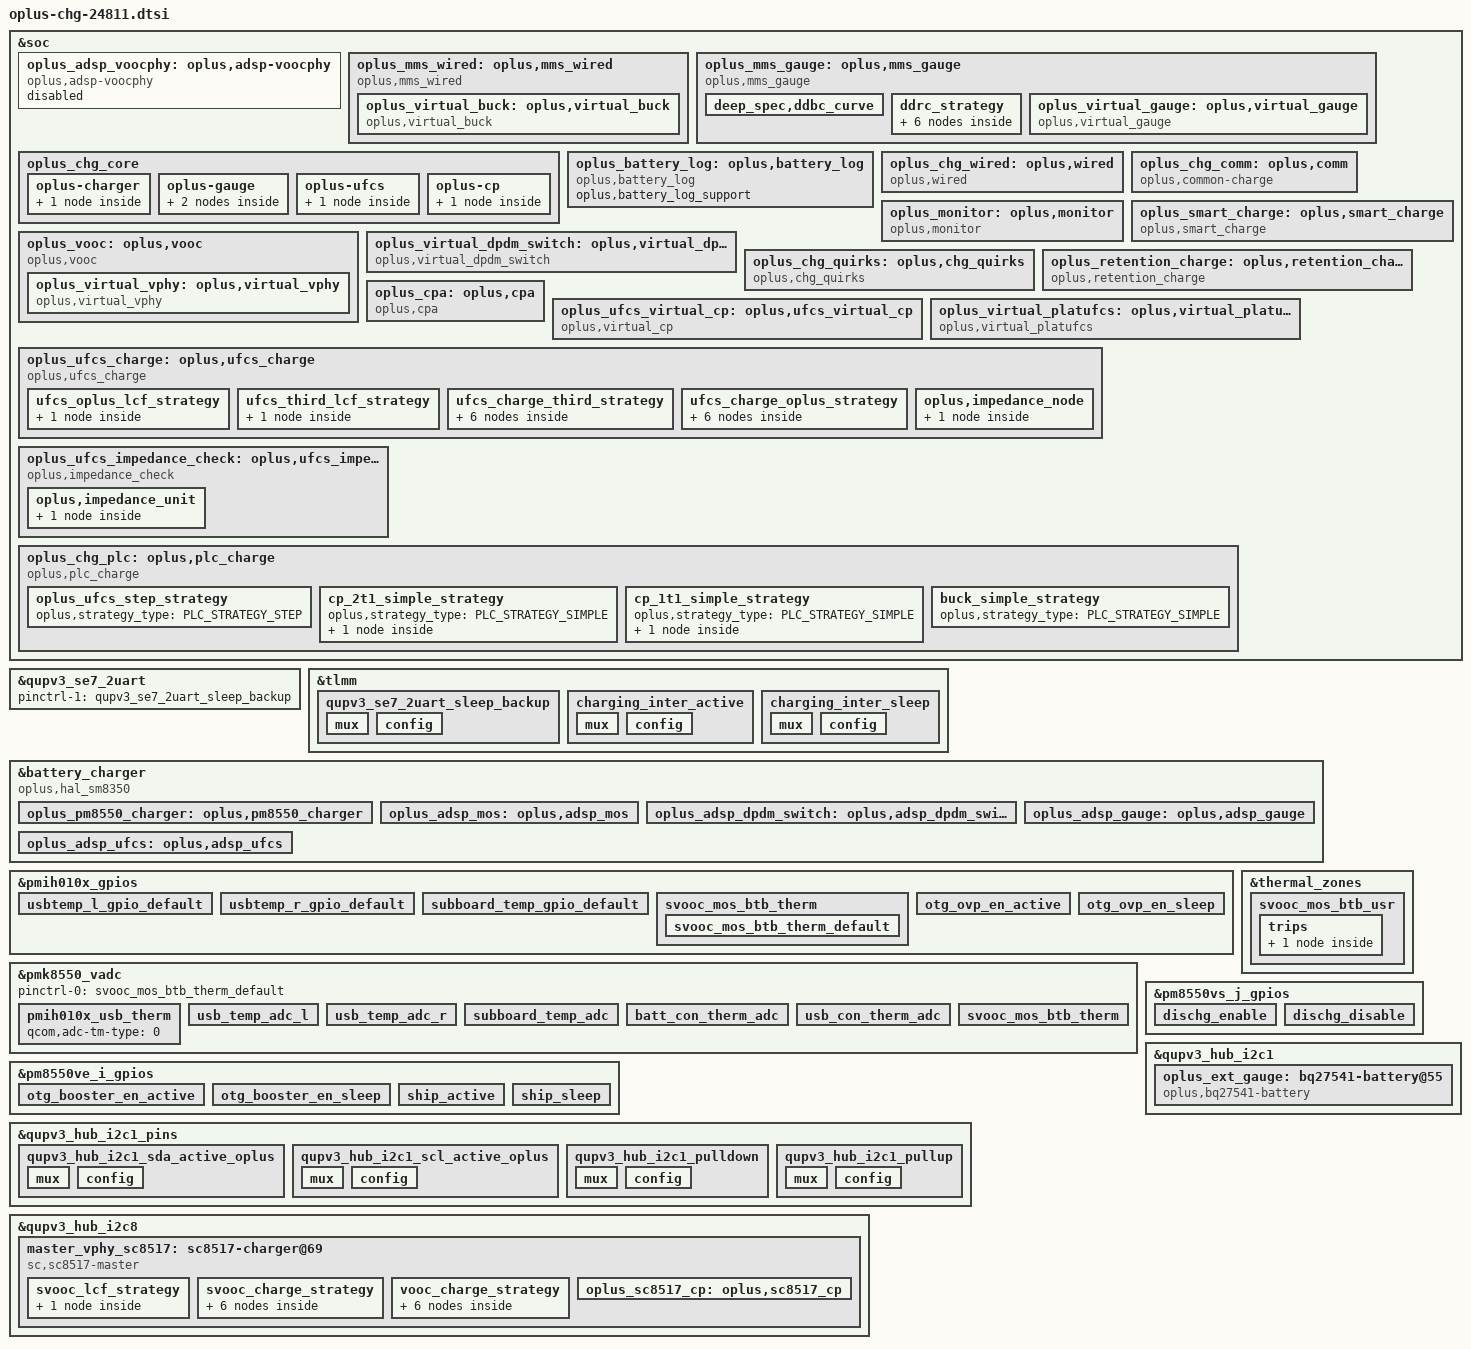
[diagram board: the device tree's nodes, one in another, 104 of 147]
//ifdef OPLUS_FEATURE_CHG_BASIC
//BSP.CHG.Basic, 2023/04/19, sjc Add for charging

#include "oplus-chg-8750.h.dtsi"
#include "oplus-chg-24019-fw.dtsi"

/*
 * NOTICE:
 * sector 1: wired charging
 * sector 2: ufcs
 * sector 3: pps
 */

//#ifdef OPLUS_FEATURE_CHG_BASIC /* BSP.CHG.Basic, 2023/04/19, sjc Add for wired charging */
//for wired charging config
&soc {
	oplus_adsp_voocphy: oplus,adsp-voocphy {
		status = "disabled";
		compatible = "oplus,adsp-voocphy";
	};

	oplus_mms_wired: oplus,mms_wired {
		compatible = "oplus,mms_wired";
		oplus,buck_ic = <&oplus_virtual_buck>;
		oplus,voocphy_ic = <&oplus_virtual_vphy>;

		oplus,adc_info_name = "855";
		oplus,topic-update-interval = <5000>;
		high-temp-scheme;

		oplus,support_usbtemp_protect_v2;
		oplus_spec,usbtemp_batt_temp_low = <50>;
		oplus_spec,usbtemp_batt_temp_high = <50>;
		oplus_spec,usbtemp_batt_temp_over_hot = <60>;
		oplus_spec,usbtemp_ntc_temp_low = <57>;
		oplus_spec,usbtemp_ntc_temp_high = <69>;
		oplus_spec,usbtemp_temp_gap_low_with_batt_temp = <7>;
		oplus_spec,usbtemp_temp_gap_with_batt_temp_in_over_hot = <15>;
		oplus_spec,usbtemp_temp_gap_high_with_batt_temp = <12>;
		oplus_spec,usbtemp_temp_gap_low_without_batt_temp = <12>;
		oplus_spec,usbtemp_temp_gap_high_without_batt_temp = <24>;
		oplus_spec.usbtemp_rise_fast_temp_low = <3>;
		oplus_spec.usbtemp_rise_fast_temp_high = <3>;
		oplus_spec.usbtemp_rise_fast_temp_count_low = <30>;
		oplus_spec.usbtemp_rise_fast_temp_count_high = <20>;
		oplus_spec,usbtemp_cool_down_ntc_low = <54>;
		oplus_spec,usbtemp_cool_down_ntc_high = <65>;
		oplus_spec,usbtemp_cool_down_gap_low = <12>;
		oplus_spec,usbtemp_cool_down_gap_high = <20>;
		oplus_spec,usbtemp_cool_down_recover_ntc_low = <48>;
		oplus_spec,usbtemp_cool_down_recover_ntc_high = <60>;
		oplus_spec,usbtemp_cool_down_recover_gap_low = <6>;
		oplus_spec,usbtemp_cool_down_recover_gap_high = <15>;
		oplus_spec,usbtemp_otg_cc_boot_current_limit = <1250>;

		oplus_virtual_buck: oplus,virtual_buck {
			compatible = "oplus,virtual_buck";
			oplus,buck_ic = <&oplus_pm8550_charger>;
			oplus,buck_ic_index = <0>;
			oplus,buck_ic_connect = <OPLUS_CHG_IC_CONNECT_PARALLEL>;
			oplus,main_charger = <1>;
			oplus,buck_ic_current_ratio = <100>;
			oplus,buck_ic_func_group = <&plat_pm8550_groups>;

			oplus,ic_type = <OPLUS_CHG_IC_VIRTUAL_BUCK>;
			oplus,ic_index = <0>;

			oplus,dischg-gpio = <&pm8550vs_j_gpios 6 0x00>;
			oplus,ship-gpio = <&pm8550ve_i_gpios 7 0x00>;
			oplus,usbtemp_conversion_ratio = <10>;

			pinctrl-names = "usbtemp_l_gpio_default", "usbtemp_r_gpio_default",
						"dischg_enable", "dischg_disable",
						"ship_active", "ship_sleep";
			pinctrl-0 = <&usbtemp_l_gpio_default>;
			pinctrl-1 = <&usbtemp_r_gpio_default>;
			pinctrl-2 = <&dischg_enable>;
			pinctrl-3 = <&dischg_disable>;
			pinctrl-4 = <&ship_active>;
			pinctrl-5 = <&ship_sleep>;

			io-channels = <&pmk8550_vadc PMIH010X_ADC5_GEN4_AMUX1_GPIO6_100K_PU>,
					      <&pmk8550_vadc PMIH010X_ADC5_GEN4_AMUX5_GPIO18_100K_PU>;
			io-channel-names = "usb_temp_adc_l", "usb_temp_adc_r";

			oplus,uart_tx-gpio = <&tlmm 62 0x00>;
			oplus,uart_rx-gpio = <&tlmm 63 0x00>;
		};
	};
	oplus_mms_gauge: oplus,mms_gauge {
		compatible = "oplus,mms_gauge";
		oplus,gauge_ic = <&oplus_virtual_gauge>;
		oplus,topic-update-interval = <5000>;
		oplus,support_subboard_ntc;

		deep_spec,support;
		deep_spec,uv_thr = <3000>;
		deep_spec,count_thr = <50>;
		deep_spec,vbat_soc = <20>;
		deep_spec,count_step = <0 10 0
					350 12 1
					450 15 2
					530 20 3>;

		deep_spec,term_coeff = <3000 800 4
					3100 900 6
					3200 1000 9
					3300 1100 10>;
		deep_spec,ddrc_strategy_name = "ddrc_curve";
		deep_spec,volt_step = <20>;
		deep_spec,ddbc_curve {
			oplus,temp_type = <OPLUS_STRATEGY_USE_BATT_TEMP>;
			oplus,temp_range = <(-100) 50 200>;
			deep_spec,ddbc_temp_cold = <500 3250 5
						   10000 3200 2>;
			deep_spec,ddbc_temp_cool = <500 3250 5
						   10000 3200 2>;
			deep_spec,ddbc_temp_normal = <500 3350 5
						   10000 3300 2>;
			deep_spec,ddbc_temp_warm = <500 3350 5
						   10000 3300 2>;
		};
		ddrc_strategy {
			oplus,temp_type = <OPLUS_STRATEGY_USE_BATT_TEMP>;
			oplus,ratio_range = <20 30 50 70 90>;
			oplus,temp_range = <(-50) 100 350>;
			strategy_ratio_range_min {
				strategy_temp_cold =	<0 3000 3000 0
							15 3000 3000 1
							1200 3100 3100 2
							1600 3200 3200 3
							2000 3300 3300 4>;
				strategy_temp_cool =	<0 3000 3000 0
							15 3000 3000 1
							500 3000 3000 2
							1000 3100 3100 3
							1500 3200 3200 4
							2000 3300 3300 5>;
				strategy_temp_normal =	<0 3000 3000 0
							15 3000 3000 1
							500 3100 3100 2
							1000 3200 3200 3
							1500 3300 3300 4>;
				strategy_temp_warm =	<0 3000 3000 0
							15 3000 3000 1
							500 3100 3100 2
							1000 3200 3200 3
							1500 3300 3300 4>;
			};
			strategy_ratio_range_low {
				strategy_temp_cold =	<0 3000 3000 0
							15 3000 3000 1
							1000 3100 3100 2
							1300 3200 3200 3
							1600 3300 3300 4>;
				strategy_temp_cool =	<0 3000 3000 0
							15 3000 3000 1
							400 3000 3000 2
							800 3100 3100 3
							1200 3200 3200 4
							1600 3300 3300 5>;
				strategy_temp_normal =	<0 3000 3000 0
							15 3000 3000 1
							400 3100 3100 2
							800 3200 3200 3
							1200 3300 3300 4>;
				strategy_temp_warm =	<0 3000 3000 0
							15 3000 3000 1
							400 3100 3100 2
							800 3200 3200 3
							1200 3300 3300 4>;
			};
			strategy_ratio_range_mid_low {
				strategy_temp_cold =	<0 3000 3000 0
							15 3000 3000 1
							600 3100 3100 2
							900 3200 3200 3
							1200 3300 3300 4>;
				strategy_temp_cool =	<0 3000 3000 0
							15 3000 3000 1
							300 3100 3100 2
							600 3200 3200 3
							900 3200 3200 4
							1200 3300 3300 5>;
				strategy_temp_normal =	<0 3000 3000 0
							15 3000 3000 1
							300 3100 3100 2
							600 3200 3200 3
							900 3300 3300 4>;
				strategy_temp_warm =	<0 3000 3000 0
							15 3000 3000 1
							300 3100 3100 2
							600 3200 3200 3
							900 3300 3300 4>;
			};
			strategy_ratio_range_mid {
				strategy_temp_cold =	<0 3000 3000 0
							15 3000 3000 1
							400 3100 3100 2
							700 3200 3200 3
							1000 3300 3300 4>;
				strategy_temp_cool =	<0 3000 3000 0
							100 3000 3000 1
							200 3100 3100 2
							500 3200 3200 3
							800 3300 3300 4>;
				strategy_temp_normal =	<0 3000 3000 0
							100 3100 3100 1
							200 3200 3200 2
							500 3300 3300 3>;
				strategy_temp_warm =	<0 3000 3000 0
							100 3100 3100 1
							200 3200 3200 2
							500 3300 3300 3>;
			};
			strategy_ratio_range_mid_high {
				strategy_temp_cold =	<0 3000 3000 0
							15 3000 3000 1
							150 3100 3100 2
							300 3200 3200 3
							500 3300 3300 4>;
				strategy_temp_cool =	<0 3000 3000 0
							50 3000 3000 1
							100 3100 3100 2
							150 3200 3200 3
							300 3300 3300 4>;
				strategy_temp_normal =	<0 3000 3000 0
							50 3100 3100 1
							100 3200 3200 2
							150 3300 3300 3>;
				strategy_temp_warm =	<0 3000 3000 0
							50 3100 3100 1
							100 3200 3200 2
							150 3300 3300 3>;
			};
			strategy_ratio_range_high {
				strategy_temp_cold =	<0 3000 3000 0
							15 3000 3000 1
							150 3100 3100 2
							300 3200 3200 3
							500 3300 3300 4>;
				strategy_temp_cool =	<0 3000 3000 0
							50 3000 3000 1
							100 3100 3100 2
							150 3200 3200 3
							300 3300 3300 4>;
				strategy_temp_normal =	<0 3000 3000 0
							50 3100 3100 1
							100 3200 3200 2
							150 3300 3300 3>;
				strategy_temp_warm =	<0 3000 3000 0
							50 3100 3100 1
							100 3200 3200 2
							150 3300 3300 3>;
			};
		};

		oplus_virtual_gauge: oplus,virtual_gauge {
			compatible = "oplus,virtual_gauge";
			oplus,gauge_ic = <&oplus_ext_gauge  &oplus_adsp_gauge>;
			oplus,gauge_ic_index = <0 1>;
			oplus,gauge_ic_func_group = <&bq27541_groups &oplus_adsp_gauge_groups>;
			oplus,batt_capacity_mah = <6100>;
			oplus,ic_type = <OPLUS_CHG_IC_VIRTUAL_GAUGE>;
			oplus,ic_index = <0>;
		};
	};
};

&soc {
	oplus_chg_core {
		oplus,chg_framework_v2;
		oplus,battery_type_by_smem;
		oplus,smart_charging_screenoff;
		oplus,chg_spec_version = <OPLUS_CHG_SPEC_VER_V3P7>;
		oplus,common-charge-icl-support;

		oplus-charger {
			plat_pm8550_groups: oplus,plat_pm8550-groups {
				functions = <
					OPLUS_IC_FUNC_INIT
					OPLUS_IC_FUNC_EXIT
					OPLUS_IC_FUNC_REG_DUMP
					OPLUS_IC_FUNC_SMT_TEST
					OPLUS_IC_FUNC_BUCK_INPUT_PRESENT
					OPLUS_IC_FUNC_BUCK_INPUT_SUSPEND
					OPLUS_IC_FUNC_BUCK_INPUT_IS_SUSPEND
					OPLUS_IC_FUNC_BUCK_OUTPUT_SUSPEND
					OPLUS_IC_FUNC_BUCK_OUTPUT_IS_SUSPEND
					OPLUS_IC_FUNC_BUCK_GET_CC_ORIENTATION
					OPLUS_IC_FUNC_BUCK_GET_CHARGER_TYPE
					OPLUS_IC_FUNC_BUCK_RERUN_BC12
					OPLUS_IC_FUNC_BUCK_QC_DETECT_ENABLE
					OPLUS_IC_FUNC_BUCK_SHIPMODE_ENABLE
					OPLUS_IC_FUNC_BUCK_SET_QC_CONFIG
					OPLUS_IC_FUNC_BUCK_SET_PD_CONFIG
					OPLUS_IC_FUNC_GET_SHUTDOWN_SOC
					OPLUS_IC_FUNC_BACKUP_SOC
					OPLUS_IC_FUNC_GET_TYPEC_MODE
					OPLUS_IC_FUNC_BUCK_SET_ICL
					OPLUS_IC_FUNC_BUCK_GET_ICL
					OPLUS_IC_FUNC_BUCK_SET_FCC
					OPLUS_IC_FUNC_BUCK_SET_FV
					OPLUS_IC_FUNC_BUCK_SET_ITERM
					OPLUS_IC_FUNC_BUCK_SET_RECHG_VOL
					OPLUS_IC_FUNC_BUCK_GET_INPUT_CURR
					OPLUS_IC_FUNC_BUCK_GET_INPUT_VOL
					OPLUS_IC_FUNC_GET_CHARGER_CYCLE
					OPLUS_IC_FUNC_OTG_BOOST_ENABLE
					OPLUS_IC_FUNC_SET_OTG_BOOST_CURR_LIMIT
					OPLUS_IC_FUNC_BUCK_GET_VBUS_COLLAPSE_STATUS
					OPLUS_IC_FUNC_GET_OTG_ENABLE
					OPLUS_IC_FUNC_SET_OTG_SWITCH_STATUS
					OPLUS_IC_FUNC_GET_OTG_SWITCH_STATUS
					OPLUS_IC_FUNC_GET_OTG_ONLINE_STATUS
					OPLUS_IC_FUNC_BUCK_GET_HW_DETECT
					OPLUS_IC_FUNC_VOOCPHY_SET_MATCH_TEMP
					OPLUS_IC_FUNC_IS_OPLUS_SVID
					OPLUS_IC_FUNC_BUCK_SET_VINDPM
					OPLUS_IC_FUNC_WLS_BOOST_ENABLE
					OPLUS_IC_FUNC_SET_WLS_BOOST_VOL
					OPLUS_IC_FUNC_SET_WLS_BOOST_CURR_LIMIT
					OPLUS_IC_FUNC_BUCK_WLS_INPUT_SUSPEND
					OPLUS_IC_FUNC_BUCK_SET_WLS_ICL
					OPLUS_IC_FUNC_BUCK_GET_WLS_ICL
					OPLUS_IC_FUNC_BUCK_GET_WLS_INPUT_CURR
					OPLUS_IC_FUNC_BUCK_GET_WLS_INPUT_VOL
					OPLUS_IC_FUNC_BUCK_WLS_AICL_ENABLE
					OPLUS_IC_FUNC_BUCK_WLS_AICL_RERUN
					OPLUS_IC_FUNC_BUCK_DIS_INSERT_DETECT
					OPLUS_IC_FUNC_GET_TYPEC_ROLE
					OPLUS_IC_FUNC_SET_TYPEC_MODE
					OPLUS_IC_FUNC_BUCK_GET_USB_BTB_TEMP
					OPLUS_IC_FUNC_BUCK_GET_BATT_BTB_TEMP
					OPLUS_IC_FUNC_BUCK_GET_USB_AICL_ENHANCE
					OPLUS_IC_FUNC_BUCK_SET_AICL_POINT
				>;
				virqs = <
					OPLUS_IC_VIRQ_ERR
					OPLUS_IC_VIRQ_CC_DETECT
					OPLUS_IC_VIRQ_PLUGIN
					OPLUS_IC_VIRQ_CC_CHANGED
					OPLUS_IC_VIRQ_SUSPEND_CHECK
					OPLUS_IC_VIRQ_CHG_TYPE_CHANGE
					OPLUS_IC_VIRQ_OTG_ENABLE
					OPLUS_IC_VIRQ_SVID
				>;
			};
		};

		oplus-gauge {
			bq27541_groups: oplus,bq27541_groups {
				functions = <
					OPLUS_IC_FUNC_INIT
					OPLUS_IC_FUNC_EXIT
					OPLUS_IC_FUNC_REG_DUMP
					OPLUS_IC_FUNC_SMT_TEST
					OPLUS_IC_FUNC_GAUGE_GET_BATT_VOL
					OPLUS_IC_FUNC_GAUGE_GET_BATT_MAX
					OPLUS_IC_FUNC_GAUGE_GET_BATT_MIN
					OPLUS_IC_FUNC_GAUGE_GET_BATT_CURR
					OPLUS_IC_FUNC_GAUGE_GET_BATT_TEMP
					OPLUS_IC_FUNC_GAUGE_GET_BATT_SOC
					OPLUS_IC_FUNC_GAUGE_GET_BATT_FCC
					OPLUS_IC_FUNC_GAUGE_GET_BATT_CC
					OPLUS_IC_FUNC_GAUGE_GET_BATT_RM
					OPLUS_IC_FUNC_GAUGE_GET_BATT_SOH
					OPLUS_IC_FUNC_GAUGE_GET_BATT_AUTH
					OPLUS_IC_FUNC_GAUGE_GET_BATT_HMAC
					OPLUS_IC_FUNC_GAUGE_SET_BATT_FULL
					OPLUS_IC_FUNC_GAUGE_UPDATE_DOD0
					OPLUS_IC_FUNC_GAUGE_UPDATE_SOC_SMOOTH
					OPLUS_IC_FUNC_GAUGE_GET_CB_STATUS
					OPLUS_IC_FUNC_GAUGE_GET_BATT_NUM
					OPLUS_IC_FUNC_GAUGE_GET_DEVICE_TYPE
					OPLUS_IC_FUNC_GAUGE_GET_DEVICE_TYPE_FOR_VOOC
					OPLUS_IC_FUNC_GAUGE_GET_BATT_FCC
					OPLUS_IC_FUNC_GAUGE_GET_BATT_FC
					OPLUS_IC_FUNC_GAUGE_GET_BATT_QM
					OPLUS_IC_FUNC_GAUGE_GET_BATT_PD
					OPLUS_IC_FUNC_GAUGE_GET_BATT_RCU
					OPLUS_IC_FUNC_GAUGE_GET_BATT_RCF
					OPLUS_IC_FUNC_GAUGE_GET_BATT_FCU
					OPLUS_IC_FUNC_GAUGE_GET_BATT_FCF
					OPLUS_IC_FUNC_GAUGE_GET_BATT_SOU
					OPLUS_IC_FUNC_GAUGE_GET_BATT_DO0
					OPLUS_IC_FUNC_GAUGE_GET_BATT_DOE
					OPLUS_IC_FUNC_GAUGE_GET_BATT_TRM
					OPLUS_IC_FUNC_GAUGE_GET_BATT_PC
					OPLUS_IC_FUNC_GAUGE_GET_BATT_QS
					OPLUS_IC_FUNC_GAUGE_IS_SUSPEND
					OPLUS_IC_FUNC_GAUGE_GET_BCC_PARMS
					OPLUS_IC_FUNC_GAUGE_FASTCHG_UPDATE_BCC_PARMS
					OPLUS_IC_FUNC_GAUGE_GET_PREV_BCC_PARMS
					OPLUS_IC_FUNC_GAUGE_SET_BCC_PARMS
					OPLUS_IC_FUNC_GAUGE_SET_PROTECT_CHECK
					OPLUS_IC_FUNC_GAUGE_GET_AFI_UPDATE_DONE
					OPLUS_IC_FUNC_GAUGE_CHECK_RESET
					OPLUS_IC_FUNC_GAUGE_SET_RESET
					OPLUS_IC_FUNC_GAUGE_GET_DEVICE_TYPE_FOR_BCC
					OPLUS_IC_FUNC_GAUGE_GET_DOD0
					OPLUS_IC_FUNC_GAUGE_GET_DOD0_PASSED_Q
					OPLUS_IC_FUNC_GAUGE_GET_QMAX
					OPLUS_IC_FUNC_GAUGE_GET_QMAX_PASSED_Q
					OPLUS_IC_FUNC_GAUGE_GET_REG_INFO
					OPLUS_IC_FUNC_GAUGE_GET_CALIB_TIME
					OPLUS_IC_FUNC_GAUGE_GET_DEEP_DISCHG_COUNT
					OPLUS_IC_FUNC_GAUGE_SET_DEEP_DISCHG_COUNT
					OPLUS_IC_FUNC_GAUGE_GET_DEEP_TERM_VOLT
					OPLUS_IC_FUNC_GAUGE_SET_DEEP_TERM_VOLT
					OPLUS_IC_FUNC_GAUGE_SET_SILI_SPARE_POWER
					OPLUS_IC_FUNC_GAUGE_GET_SILI_SIMULATE_TERM_VOLT
					OPLUS_IC_FUNC_GAUGE_GET_SILI_IC_ALG_TERM_VOLT
					OPLUS_IC_FUNC_GAUGE_SET_SILI_IC_ALG_CFG
					OPLUS_IC_FUNC_GAUGE_GET_SILI_IC_ALG_DSG_ENABLE
					OPLUS_IC_FUNC_GAUGE_SET_SILI_IC_ALG_TERM_VOLT
					OPLUS_IC_FUNC_GAUGE_GET_SILI_ALG_APPLICATION_INFO
					OPLUS_IC_FUNC_GAUGE_GET_SILI_LIFETIME_STATUS
					OPLUS_IC_FUNC_GAUGE_GET_SILI_LIFETIME_INFO
					OPLUS_IC_FUNC_GAUGE_SET_LAST_CC
					OPLUS_IC_FUNC_GAUGE_GET_LAST_CC
					OPLUS_IC_FUNC_GAUGE_GET_CHEM_ID
				>;
				virqs = <
					OPLUS_IC_VIRQ_ERR
					OPLUS_IC_VIRQ_OFFLINE
					OPLUS_IC_VIRQ_RESUME
				>;
			};
			oplus_adsp_gauge_groups: oplus,oplus_adsp_gauge_groups {
				functions = <
					OPLUS_IC_FUNC_INIT
					OPLUS_IC_FUNC_EXIT
					OPLUS_IC_FUNC_REG_DUMP
					OPLUS_IC_FUNC_SMT_TEST
					OPLUS_IC_FUNC_GAUGE_GET_SUBBOARD_TEMP
				>;
				virqs = <
					OPLUS_IC_VIRQ_ERR
				>;
			};
		};

		oplus-ufcs {
			adsp_ufcs_groups: oplus,ufcs_groups {
				functions = <
					OPLUS_IC_FUNC_INIT
					OPLUS_IC_FUNC_EXIT
					OPLUS_IC_FUNC_REG_DUMP
					OPLUS_IC_FUNC_SMT_TEST
					OPLUS_IC_FUNC_UFCS_HANDSHAKE
					OPLUS_IC_FUNC_UFCS_PDO_SET
					OPLUS_IC_FUNC_UFCS_HARD_RESET
					OPLUS_IC_FUNC_UFCS_EXIT
					OPLUS_IC_FUNC_UFCS_CONFIG_WD
					OPLUS_IC_FUNC_UFCS_GET_DEV_INFO
					OPLUS_IC_FUNC_UFCS_GET_ERR_INFO
					OPLUS_IC_FUNC_UFCS_GET_SRC_INFO
					OPLUS_IC_FUNC_UFCS_GET_CABLE_INFO
					OPLUS_IC_FUNC_UFCS_GET_PDO_INFO
					OPLUS_IC_FUNC_UFCS_VERIFY_ADAPTER
					OPLUS_IC_FUNC_UFCS_GET_POWER_CHANGE_INFO
					OPLUS_IC_FUNC_UFCS_GET_EMARK_INFO
					OPLUS_IC_FUNC_UFCS_GET_POWER_INFO_EXT
					OPLUS_IC_FUNC_UFCS_IS_TEST_MODE
				>;
				virqs = <
					OPLUS_IC_VIRQ_ERR
					OPLUS_IC_VIRQ_ONLINE
					OPLUS_IC_VIRQ_OFFLINE
				>;
			};
		};

		oplus-cp {
			adsp_mos_groups: oplus,mos_groups {
			functions = <
					OPLUS_IC_FUNC_INIT
					OPLUS_IC_FUNC_EXIT
					OPLUS_IC_FUNC_CP_GET_TEMP
				>;
				virqs = <
					OPLUS_IC_VIRQ_ERR
					OPLUS_IC_VIRQ_ONLINE
					OPLUS_IC_VIRQ_OFFLINE
				>;
			};
		};
	};
};

&qupv3_se7_2uart {
	pinctrl-1 = <&qupv3_se7_2uart_sleep_backup>;
	status = "okay";
};

&tlmm {
	qupv3_se7_2uart_sleep_backup:qupv3_se7_2uart_sleep_backup {
		mux {
			pins = "gpio62", "gpio63";
			function = "gpio";
		};

		config {
			pins = "gpio62", "gpio63";
			drive-strength = <2>;
			bias-disable;
			input-enable;
		};
	};
};

&battery_charger {
	//for oplus chg framework:
	oplus,chg_ops = "plat-pmic";
	qcom,pmic_ftm_vph = "/sys/bus/spmi/drivers/pmic-spmi/0-00/c42d000.qcom,spmi:qcom,pmk8550@0:vadc@9000/iio:device0/in_voltage_pmih010x_vph_pwr_input";
	qcom,pmic_ftm_vbat = "/sys/bus/spmi/drivers/pmic-spmi/0-00/c42d000.qcom,spmi:qcom,pmk8550@0:vadc@9000/iio:device0/in_voltage_pmih010x_vbat_sns_qbg_input";
	oplus,usb_aicl_enhance;

	//qcom,otg-booster-en-gpio = <&pm8550ve_i_gpios 8 0x00>;
	//qcom,otg-ovp-en-gpio = <&pmih010x_gpios 11 0x00>;
	//oplus,wrx_otg_en-gpio = <&pm8550_gpios 1 0x00>;//wls nor OVP check
	//pinctrl-names = "otg_booster_en_active", "otg_booster_en_sleep",
	//		"otg_ovp_en_active", "otg_ovp_en_sleep",
	//		"subboard_temp_gpio_default";
	//pinctrl-0 = <&otg_booster_en_active>;
	//pinctrl-1 = <&otg_booster_en_sleep>;
	//pinctrl-2 = <&otg_ovp_en_active>;
	//pinctrl-3 = <&otg_ovp_en_sleep>;
	//pinctrl-4 = <&subboard_temp_gpio_default>;
	//pinctrl-5 = <&wrx_otg_en_active>;
	//pinctrl-6 = <&wrx_otg_en_sleep>;

};

&battery_charger {
	compatible = "oplus,hal_sm8350";
	//oplus,vphy_ic = <&oplus_adsp_voocphy>;
	oplus,voocphy_support;
	//oplus,vooc_project = <8>;
	oplus,voocphy_bidirect_cp_support;
	oplus,batt_num = <2>;
	oplus,otg_scheme = <0>;//0:cid 1:ccdetect_gpio 2:switch
	oplus,ufcs_run_check_support;

	oplus_pm8550_charger: oplus,pm8550_charger {
		oplus,ic_type = <OPLUS_CHG_IC_BUCK>;
		oplus,ic_index = <0>;
	};
	oplus_adsp_mos: oplus,adsp_mos {
		oplus,ic_type = <OPLUS_CHG_IC_CP>;
		oplus,ic_index = <0>;
		oplus,ic_func_group = <&adsp_mos_groups>;
	};
	oplus_adsp_dpdm_switch: oplus,adsp_dpdm_switch {
		oplus,ic_type = <OPLUS_CHG_IC_MISC>;
		oplus,ic_index = <0>;
	};
	oplus_adsp_gauge: oplus,adsp_gauge {
		oplus,ic_type = <OPLUS_CHG_IC_GAUGE>;
		oplus,ic_index = <0>;
	};
	oplus_adsp_ufcs: oplus,adsp_ufcs {
		oplus,ic_type = <OPLUS_CHG_IC_UFCS>;
		oplus,ic_index = <0>;
	};
};

&soc {
	oplus_battery_log: oplus,battery_log {
		compatible = "oplus,battery_log";

		oplus,battery_log_support;
	};

	oplus_chg_wired: oplus,wired {
		compatible = "oplus,wired";

		oplus,vooc-support;

		oplus_spec,vbatt_pdqc_to_5v_thr = <5100>;
		oplus_spec,vbatt_pdqc_to_9v_thr = <5000>;
		oplus_spec,pd-iclmax-ma = <2000>;
		oplus_spec,qc-iclmax-ma = <2000>;
		oplus_spec,non-standard-ibatmax-ma = <1000>;
		oplus_spec,input-power-mw = <
			2500		/* OPLUS_WIRED_CHG_MODE_UNKNOWN */
			2500		/* OPLUS_WIRED_CHG_MODE_SDP */
			7500		/* OPLUS_WIRED_CHG_MODE_CDP */
			10000		/* OPLUS_WIRED_CHG_MODE_DCP */
			15000		/* OPLUS_WIRED_CHG_MODE_VOOC */
			18000		/* OPLUS_WIRED_CHG_MODE_QC */
			18000		/* OPLUS_WIRED_CHG_MODE_PD */
		>;
		oplus_spec,led_on-fccmax-ma = <0 1340 4000 4400 4400 4400 4400 1000 0>;
		oplus_spec,fccmax-ma-lv = <
			0 521 2200 2200 2200 2200 2200 2200 0	/* OPLUS_WIRED_CHG_MODE_UNKNOWN */
			0 521  600  600  600  600  600  600  0	/* OPLUS_WIRED_CHG_MODE_SDP */
			0 521 1600 1600 1600 1600 1600 1600 0	/* OPLUS_WIRED_CHG_MODE_CDP */
			0 521 2200 2200 2200 2200 2200 2200 0	/* OPLUS_WIRED_CHG_MODE_DCP */
			0 521 2606 3300 3300 3300 3300 3185 0	/* OPLUS_WIRED_CHG_MODE_VOOC */
			0 521 2606 4169 4400 4400 4400 3185 0	/* OPLUS_WIRED_CHG_MODE_QC */
			0 521 2606 4169 4400 4400 4400 3185 0	/* OPLUS_WIRED_CHG_MODE_PD */
		>;
		oplus_spec,fccmax-ma-hv = <
			0 521 1042 1563 2200 2200 2200 1000 0	/* OPLUS_WIRED_CHG_MODE_UNKNOWN */
			0 521 600  600  600  600  600  600  0	/* OPLUS_WIRED_CHG_MODE_SDP */
			0 521 1042 1563 1600 1600 1600 600 0	/* OPLUS_WIRED_CHG_MODE_CDP */
			0 521 1042 1563 2200 2200 2200 1000 0	/* OPLUS_WIRED_CHG_MODE_DCP */
			0 521 1042 1563 2606 3300 3300 1000 0	/* OPLUS_WIRED_CHG_MODE_VOOC */
			0 521 1042 1563 2606 4400 4400 1000 0	/* OPLUS_WIRED_CHG_MODE_QC */
			0 521 1042 1563 2606 4400 4400 1000 0	/* OPLUS_WIRED_CHG_MODE_PD */
		>;

		oplus_spec,cool_down_sale_pdqc_vol_mv = <9000>;
		oplus_spec,cool_down_sale_pdqc_curr_ma = <1200>;
		oplus_spec,cool_down_pdqc_vol_mv = <9000 9000 9000>;
		oplus_spec,cool_down_pdqc_curr_ma = <1200 1500 2000>;
		oplus_spec,cool_down_vooc_curr_ma = <1500 1500 2000 2500 3000 3500>;
		oplus_spec,cool_down_normal_curr_ma = <1200 1500 2000>;

		oplus_spec,vbus_ov_thr_mv = <11000 11000>;
		oplus_spec,vbus_uv_thr_mv = <4300 4300>;

		/* first data is strategy used temp type */
		oplus,vooc_strategy_name = "cgcl";
		oplus,vooc_strategy_data = <OPLUS_STRATEGY_USE_BATT_TEMP
					    0   350 3000 1 0
					    330 370 3000 2 0
					    350 440 2200 2 1>;
	};

	oplus_chg_comm: oplus,comm {
		compatible = "oplus,common-charge";
		oplus_spec,dec-vol-cc-thr = <0 400 800>;
		oplus_spec,dec-vol-fv-mv = <0  0  0  0  0  0  0  0  0
					    20 20 20 20 20 20 20 0  0
					    40 40 40 40 40 40 20 0  0>;
		oplus_spec,dec-vol-wired-ffc-mv = <0  0  0
						   20 20 20
						   40 40 20>;
		oplus_spec,batt-them-thr = <(-100) 0 50 120 160 350 450 530>;
		oplus_spec,iterm-ma = <155>;
		oplus_spec,fv-mv = <4500 4500 4500 4500 4500 4500 4475 4130 4130>;
		oplus_spec,sw-fv-mv = <4450 4450 4450 4450 4450 4450 4425 4080 4080>;
		oplus_spec,hw-fv-inc-mv = <0 18 18 18 18 18 18 18 0>;
		oplus_spec,sw-over-fv-mv = <4510 4510 4510 4510 4510 4510 4485 4140 4140>;
		oplus_spec,sw-over-fv-dec-mv = <10>;
		oplus_spec,non-standard-sw-fv-mv = <3930>;
		oplus_spec,non-standard-fv-mv = <3980>;
		oplus_spec,non-standard-hw-fv-inc-mv = <18>;
		oplus_spec,non-standard-sw-over-fv-mv = <3990>;
		oplus_spec,non-standard-vbatdet-mv = <3680>;
		oplus_spec,wired-vbatdet-mv = <0 4200 4300 4400 4400 4400 4375 4030 0>;
		oplus_spec,fcc-gear-thr-mv = <4180>;
		oplus_spec,fcc-gear-shake-mv = <400 400 400 300 300 180 180 180 180>;
		oplus_spec,vbatt-ov-thr-mv = <4600>;
		oplus_spec,full_pre_ffc_judge;
		oplus_spec,full-pre-ffc-mv = <4495>;
		oplus_spec,ffc-temp-thr = <120 210 350 440>;
		oplus_spec,wired-ffc-step-max = <2>;
		oplus_spec,wired-ffc-fv-mv = <4590 4590>;

		oplus_spec,wired-ffc-fv-cutoff-mv = <4550 4525 4490
						     4520 4505 4475>;

		oplus_spec,removed_bat_decidegc = <390>;

		oplus_spec,wired-ffc-fcc-ma = <1100 1100 1100
					       700 700 700>;
		oplus_spec,wired-ffc-fcc-cutoff-ma = <400 400 400
						      200 200 200>;
		oplus_spec,drop_soc_2_temp_ladder = <(-50) 0 0 0 0 0 0 0 0 0>;
		oplus_spec,volt_diff_ladder_of_drop_soc_2 = <80 80 0 0 0 0 0 0 0 0>;
		oplus_spec,keep_soc_2_temp_ladder = <(-200) (-50) 0 0 0 0 0 0 0 0>;
		oplus_spec,volt_diff_ladder_of_keep_soc_2 = <10 20 30 0 0 0 0 0 0 0>;
		oplus_spec,back_rm_of_drop_soc_2 = <30>;
		oplus_spec,back_rm_of_drop_soc_1 = <0>;
		oplus_spec,load_current_of_drop_soc_2 = <500>;
		oplus_spec,load_current_of_drop_soc_1 = <1000>;
		oplus_spec,current_limit_of_drop_soc_2 = <350>;
		oplus_spec,volt_of_fast_drop_soc_1 = <2900>;
		oplus_spec,support_uisoc_low_battery_control;

		oplus_spec,vbat_uv_thr_mv = <3000>;
		oplus_spec,vbat_charging_uv_thr_mv = <2900>;

		/*If use subboard NTC as battery temp, config it as 20, otherwise 0 */
		oplus_spec,tbatt_power_off_cali_temp = <0>;
		oplus,vooc_show_ui_soc_decimal;
		oplus_spec,poweroff_high_batt_temp = <720>;
		oplus_spec,poweroff_emergency_batt_temp = <770>;
		oplus,ui_soc_decimal_speedmin = <20>;

		oplus,gauge_stuck_jump_support;
		oplus,gauge_stuck_threshold = <15>;
		oplus,gauge_stuck_time = <50>;

		oplus_spec,sw_check_full_cnt = <12>;
		oplus,smooth_switch;
		oplus,reserve_chg_soc = <2>;
		oplus,reserve_dis_soc = <2>;

		oplus,ui_soc_2_voltage_comp_mv = <30>;
		oplus,chg_shutdown_max_mv = <3000>;
	};

	oplus_monitor: oplus,monitor {
		compatible = "oplus,monitor";
		oplus,topic-update-interval = <60000>;

		track,fast_chg_break_t_thd = <1400>;
		track,general_chg_break_t_thd = <300>;
		track,voocphy_type = <2>;
		track,wired_max_power = <100000>;
		track,wired_fast_chg_scheme = <0>;

		track,gauge_status_ctrl;
		track,external_gauge_num = <1>;
	};

	oplus_vooc: oplus,vooc {
		compatible = "oplus,vooc";
		oplus,vooc_ic = <&oplus_virtual_vphy>;

		oplus_spec,vooc_soc_range = <50 75 85>;
		oplus_spec,vooc_temp_range = <50 120 180 350 450>;

		oplus,vooc_data_width = <7>;
		oplus,vooc_curr_max = <CURR_LIMIT_7BIT_9_5A>;
		oplus,support_vooc_by_normal_charger_path;
		oplus,vooc_project = <8>;
		oplus,vooc_power_max_w = <100>;
		oplus,voocphy_support = <2>;
		oplus,support_fake_vooc_check;
		oplus,subboard_ntc_abnormal_current = <7300>;
		oplus,smart_chg_bcc_support;

		oplus,abnormal_adapter_current = <CURR_LIMIT_7BIT_9_5A CURR_LIMIT_7BIT_9_5A
						CURR_LIMIT_7BIT_5_0A CURR_LIMIT_7BIT_5_0A
						CURR_LIMIT_7BIT_4_0A CURR_LIMIT_7BIT_4_0A
						CURR_LIMIT_7BIT_3_0A CURR_LIMIT_7BIT_3_0A
						CURR_LIMIT_7BIT_2_0A CURR_LIMIT_7BIT_2_0A>;

		oplus,abnormal_over_80w_adapter_current = <CURR_LIMIT_7BIT_9_5A CURR_LIMIT_7BIT_9_5A
						CURR_LIMIT_7BIT_7_0A CURR_LIMIT_7BIT_7_0A
						CURR_LIMIT_7BIT_6_0A CURR_LIMIT_7BIT_6_0A
						CURR_LIMIT_7BIT_5_0A CURR_LIMIT_7BIT_5_0A
						CURR_LIMIT_7BIT_4_0A CURR_LIMIT_7BIT_4_0A
						CURR_LIMIT_7BIT_3_0A CURR_LIMIT_7BIT_3_0A
						CURR_LIMIT_7BIT_2_0A CURR_LIMIT_7BIT_2_0A>;

		oplus,general_strategy_name = "cgcl";
		oplus,general_strategy_data = < OPLUS_STRATEGY_USE_SHELL_TEMP
						0   380 CURR_LIMIT_7BIT_9_5A 1 0
						370 400 CURR_LIMIT_7BIT_7_0A 2 0
						390 420 CURR_LIMIT_7BIT_5_0A 3 1
						410 430 CURR_LIMIT_7BIT_4_0A 4 2
						420 440 CURR_LIMIT_7BIT_3_0A 4 3 >;

		oplus,plc_strategy-data = <&buck_simple_strategy &cp_2t1_simple_strategy &cp_1t1_simple_strategy>;
		oplus,plc_strategy-names = "default", "svooc", "vooc";

		oplus_virtual_vphy: oplus,virtual_vphy {
			compatible = "oplus,virtual_vphy";
			oplus,vphy_ic = <&master_vphy_sc8517>;
			oplus,dpdm_switch_ic = <&oplus_virtual_dpdm_switch>;

			oplus,ic_type = <OPLUS_CHG_IC_VIRTUAL_VPHY>;
			oplus,ic_index = <0>;
		};
	};

	oplus_virtual_dpdm_switch: oplus,virtual_dpdm_switch {
		compatible = "oplus,virtual_dpdm_switch";
		oplus,ic_type = <OPLUS_CHG_IC_MISC>;
		oplus,ic_index = <0>;
		oplus,use_audio_switch;
	};

	oplus_smart_charge: oplus,smart_charge {
		compatible = "oplus,smart_charge";
		oplus,quick_mode_gain_support;
		oplus,smart_chg_soh_support;
	};
	oplus_chg_quirks: oplus,chg_quirks {
		compatible = "oplus,chg_quirks";
	};
	oplus_retention_charge: oplus,retention_charge {
		compatible = "oplus,retention_charge";
		oplus,topic-update-interval = <5000>;
		oplus,support_retention_name = "oplus_retention_quirks";
	};
};

&pmih010x_gpios {
	usbtemp_l_gpio_default: usbtemp_l_gpio_default {
		pins = "gpio6"; //GPIO 6
		function = "normal"; //normal
		bias-high-impedance; //DISABLE GPIO5 for ADC
		bias-disable;
	};
	usbtemp_r_gpio_default: usbtemp_r_gpio_default {
		pins = "gpio18"; //GPIO 18
		function = "normal"; //normal
		bias-high-impedance; //DISABLE GPIO10 for ADC
		bias-disable;
	};
	subboard_temp_gpio_default: subboard_temp_gpio_default {
		pins = "gpio12"; //GPIO 12
		function = "normal"; //normal
		bias-high-impedance; //DISABLE GPIO6 for ADC
		bias-disable;
	};
	svooc_mos_btb_therm {
		svooc_mos_btb_therm_default: svooc_mos_btb_therm_default {
			pins = "gpio15";
			function = "normal"; //normal
			bias-high-impedance;
			bias-disable;
		};
	};

};

&pmk8550_vadc {
	pinctrl-0 = <&svooc_mos_btb_therm_default>;
	pinctrl-names = "default";

    pmih010x_usb_therm { //for PMIH010X_ADC5_GEN4_AMUX_THM4_USB_THERM_100K_PU
		qcom,adc-tm-type = <0>;
	};

	usb_temp_adc_l {
		reg = <PMIH010X_ADC5_GEN4_AMUX1_GPIO6_100K_PU>;
		label = "usb_temp_adc_l";
		qcom,pre-scaling = <1 1>;
		qcom,hw-settle-time = <200>;
		qcom,adc5-gen4;
		qcom,scale-fn-type = <OPLUS_ADC_SCALE_HW_CALIB_DEFAULT>;
	};
	usb_temp_adc_r {
		reg = <PMIH010X_ADC5_GEN4_AMUX5_GPIO18_100K_PU>;
		label = "usb_temp_adc_r";
		qcom,pre-scaling = <1 1>;
		qcom,hw-settle-time = <200>;
		qcom,adc5-gen4;
		qcom,scale-fn-type = <OPLUS_ADC_SCALE_HW_CALIB_DEFAULT>;
	};

	subboard_temp_adc {
		reg = <PMIH010X_ADC5_GEN4_AMUX4_GPIO12_100K_PU>;
		label = "subboard_temp_adc";
		qcom,pre-scaling = <1 1>;
		qcom,ratiometric;
		qcom,hw-settle-time = <200>;
		qcom,adc5-gen4;
	};
	batt_con_therm_adc {
		reg = <PMIH010X_ADC5_GEN4_AMUX_THM1_BAT_THERM_100K_PU>;
		label = "batt_con_therm_adc";
		qcom,ratiometric;
		qcom,hw-settle-time = <200>;
		qcom,pre-scaling = <1 1>;
		qcom,adc-tm-type = <0>;
		qcom,adc5-gen4;
	};
	usb_con_therm_adc {
		reg = <PMIH010X_ADC5_GEN4_AMUX_THM4_USB_THERM_100K_PU>;
		label = "usb_con_therm_adc";
		qcom,ratiometric;
		qcom,hw-settle-time = <200>;
		qcom,pre-scaling = <1 1>;
		qcom,adc-tm-type = <0>;
		qcom,adc5-gen4;
	};
	svooc_mos_btb_therm {
		reg = <PMIH010X_ADC5_GEN4_AMUX2_BAT2_ID_100K_PU>;
		label = "svooc_mos_btb_therm";
		qcom,ratiometric;
		qcom,hw-settle-time = <200>;
		qcom,pre-scaling = <1 1>;
		qcom,adc-tm-type = <1>;
		qcom,adc5-gen4;
	};
};

&thermal_zones {
	svooc_mos_btb_usr {
		polling-delay-passive = <0>;
		polling-delay = <0>;
		thermal-sensors = <&pmk8550_vadc PMIH010X_ADC5_GEN4_AMUX2_BAT2_ID_100K_PU>;
		trips {
			active-config0 {
				temperature = <125000>;
				hysteresis = <1000>;
				type = "passive";
			};
		};
	};
};

&battery_charger {
	io-channels	= <&pmk8550_vadc PMIH010X_ADC5_GEN4_AMUX1_GPIO6_100K_PU>,
					<&pmk8550_vadc PMIH010X_ADC5_GEN4_AMUX5_GPIO18_100K_PU>,
					<&pmk8550_vadc PMIH010X_ADC5_GEN4_AMUX4_GPIO12_100K_PU>,
					<&pmk8550_vadc PMIH010X_ADC5_GEN4_AMUX_THM1_BAT_THERM_100K_PU>,
					<&pmk8550_vadc PMIH010X_ADC5_GEN4_AMUX_THM4_USB_THERM_100K_PU>,
					<&pmk8550_vadc PMIH010X_ADC5_GEN4_AMUX2_BAT2_ID_100K_PU>;
	io-channel-names = "usb_temp_adc_l", "usb_temp_adc_r", "subboard_temp_adc",
			   "batt_con_therm_adc", "usb_con_therm_adc", "svooc_mos_btb_therm";
};

&pm8550vs_j_gpios {
	dischg_enable: dischg_enable {
		pins = "gpio6";
		function = "normal";
		bias-disable;
		power-source = <0>;
		output-high;
		qcom,drive-strength = <3>;
	};
	dischg_disable: dischg_disable {
		pins = "gpio6";
		function = "normal";
		bias-disable;
		power-source = <0>;
		output-low;
		qcom,drive-strength = <3>;
	};
};

&pm8550ve_i_gpios {
	otg_booster_en_active: otg_booster_en_active {
		pins = "gpio8";
		function = "normal";
		bias-disable;
		power-source = <0>;
		output-high;
		qcom,drive-strength = <3>;
	};
	otg_booster_en_sleep: otg_booster_en_sleep {
		pins = "gpio8";
		function = "normal";
		bias-disable;
		power-source = <0>;
		output-low;
		qcom,drive-strength = <3>;
	};
	ship_active: ship_active {
		pins = "gpio7";
		function = "normal";
		bias-disable;
		power-source = <0>;
		output-high;
		qcom,drive-strength = <2>;
	};
	ship_sleep: ship_sleep {
		pins = "gpio7";
		function = "normal";
		bias-disable;
		power-source = <0>;
		output-low;
		qcom,drive-strength = <2>;
	};
};

&pmih010x_gpios {
	otg_ovp_en_active: otg_ovp_en_active {
		pins = "gpio11";
		function = "normal";
		bias-disable;
		power-source = <0>;
		output-high;
		qcom,drive-strength = <3>;
	};
	otg_ovp_en_sleep: otg_ovp_en_sleep {
		pins = "gpio11";
		function = "normal";
		bias-disable;
		power-source = <0>;
		output-low;
		qcom,drive-strength = <3>;
	};
};
&qupv3_hub_i2c1_pins {
	qupv3_hub_i2c1_sda_active_oplus: qupv3_hub_i2c1_sda_active_oplus {
		mux {
			pins = "gpio66";
			function = "i2chub0_se1_l0";
		};

		config {
			pins = "gpio66";
			drive-strength = <2>;
			bias-pull-up;
		};
	};

	qupv3_hub_i2c1_scl_active_oplus: qupv3_hub_i2c1_scl_active_oplus {
		mux {
			pins = "gpio67";
			function = "i2chub0_se1_l1";
		};

		config {
			pins = "gpio67";
			drive-strength = <2>;
			bias-pull-up;
		};
	};

	qupv3_hub_i2c1_pulldown: qupv3_hub_i2c1_pulldown {
		mux {
			pins = "gpio66", "gpio67";
			function = "gpio";
		};

		config {
			pins = "gpio66", "gpio67";
			drive-strength = <2>;
			bias-pull-down;
			output-low;
		};
	};

	qupv3_hub_i2c1_pullup: qupv3_hub_i2c1_pullup {
		mux {
			pins = "gpio66", "gpio67";
			function = "gpio";
		};

		config {
			pins = "gpio66", "gpio67";
			drive-strength = <2>;
			bias-pull-up;
			input-enable;
		};
	};
};

&qupv3_hub_i2c1 {
	status = "ok";
	qcom,clk-freq-out = <100000>;
	pinctrl-names = "default", "sleep", "pulldown", "pullup";
	pinctrl-0 = <&qupv3_hub_i2c1_sda_active_oplus>, <&qupv3_hub_i2c1_scl_active_oplus>;
	pinctrl-1 = <&qupv3_hub_i2c1_sleep>;
	pinctrl-2 = <&qupv3_hub_i2c1_pulldown>;
	pinctrl-3 = <&qupv3_hub_i2c1_pullup>;

	oplus_ext_gauge: bq27541-battery@55 {
		status = "okay";
		compatible = "oplus,bq27541-battery";
		reg = <0x55>;
		qcom,modify-soc-smooth;
		qcom,modify-soc-calibration;
		qcom,sha1_key_index = <1>;
		qcom,batt_bq28z610;
		oplus,remove_iterm_taper;
		oplus,fcc_too_small_check_support;
		oplus,batt_num = <2>;
		qcom,gauge_num = <0>;
		oplus,bq28z610_afi_buf = /bits/ 8 <
			/* checksum data_len data+ */
			0xfd 0x04 0xf4 0x46 0xc8 0x00 /* Charge Term Taper Current 200mA */
			>;

		oplus,ic_type = <OPLUS_CHG_IC_GAUGE>;
		oplus,ic_index = <0>;
	};
};

&tlmm {
	charging_inter_active: charging_inter_active {
		mux {
			pins = "gpio163";  /* SC8517_INT*/
			function = "gpio";
		};
		config {
			pins = "gpio163";
			bias-pull-up; /* NO pull */
			drive-strength = <2>; /* 2 MA */
			input-enable;
		};
	};

	charging_inter_sleep: charging_inter_sleep {
		mux {
			pins = "gpio163"; /* SC8517_INT*/
			function = "gpio";
		};
		config {
			pins = "gpio163";
			bias-pull-up; /* NO pull */
			drive-strength = <2>; /* 2 MA */
			input-enable;
		};
	};
};

&qupv3_hub_i2c8 {
	status = "okay";
	qcom,clk-freq-out = <400000>;
	pinctrl-names = "default", "sleep";
	pinctrl-0 = <&qupv3_hub_i2c8_sda_active>, <&qupv3_hub_i2c8_scl_active>;
	pinctrl-1 = <&qupv3_hub_i2c8_sleep>;

	master_vphy_sc8517: sc8517-charger@69{
		status = "okay";
		compatible = "sc,sc8517-master";
		reg = <0x69>;

		oplus,irq_gpio = <&tlmm 163 0x00>;
		oplus,v2x_volt_full_open_low;

		pinctrl-names = "charging_inter_active", "charging_inter_sleep";
		pinctrl-0 = <&charging_inter_active>;
		pinctrl-1 = <&charging_inter_sleep>;

		oplus,ic_type = <OPLUS_CHG_IC_VPHY>;
		oplus,ic_index = <0>;
		oplus,vooc-version = <VOOC_VERSION_5_0>;

		oplus_spec,external_gauge_support;
		oplus_spec,voocphy_bidirect_cp_support;
		oplus_spec,voocphy_current_default = <91>;
		oplus_spec,ap_control_allow;

		oplus_spec,svooc_cool_down_current_limit = <91 15 15 20 25 30 35 40 45 50 55 60 63 65 70 75 80 85 91>;
		oplus_spec,vooc_cool_down_current_limit = <61 20 20 20 30 40 50 60>;

		oplus_spec,vooc_little_cold_full_voltage = <4570>;
		oplus_spec,vooc_cool_full_voltage = <4570>;
		oplus_spec,vooc_little_cool_full_voltage = <4570>;
		oplus_spec,vooc_little_cool_high_full_voltage = <4570>;
		oplus_spec,vooc_warm_full_voltage = <4130>;
		oplus_spec,vooc_1time_full_voltage = <4585>;
		oplus_spec,vooc_ntime_full_voltage = <4575>;
		oplus_spec,full_voltage = < /* vol_1time vol_ntime */
					4580 4570 /* 0 ~ 5 */
					4580 4570 /* 5 ~ 12 */
					4580 4570 /* 12 ~ 16 */
					4580 4570 /* 16 ~ 20 */
					4585 4575 /* 20 ~ 35 */
					4580 4570 /* 35 ~ 44 */
					4140 4130 /* 44 ~ 51 */
					>;

		oplus_spec,vooc_multistep_initial_batt_temp = <1000>;
		oplus_spec,vooc_little_cool_temp = <160>;
		oplus_spec,vooc_little_cool_high_temp = <210>;
		oplus_spec,vooc_cool_temp = <120>;
		oplus_spec,vooc_little_cold_temp = <50>;
		oplus_spec,vooc_normal_low_temp = <350>;
		oplus_spec,vooc_strategy_normal_current = <100>;
		oplus_spec,vooc_normal_to_little_cool_current = <100>;
		oplus_spec,vooc_over_high_temp = <510>;
		oplus_spec,vooc_low_temp = <50>;
		oplus_spec,vooc_high_temp = <500>;
		oplus_spec,vooc_low_soc = <0>;
		oplus_spec,vooc_high_soc = <95>;
		oplus_spec,vooc_normal_high_temp = <440>;
		oplus_spec,vooc_warm_vol_thr = <4000>;
		oplus_spec,vooc_warm_soc_thr = <55>;
		oplus_spec,impedance_calculation_newmethod;
		oplus_spec,svooc_circuit_r_l = <0x18>;
		oplus_spec,svooc_circuit_r_h = <0x2>;/* 65 mR */

		oplus_spec,fastchg_timeout_time_init = <148880>;
		oplus_spec,voocphy_ibat_over_current = <10500>;
		oplus_spec,voocphy_cp_max_ibus = <10500>;
		oplus_spec,voocphy_svooc_cp_max_ibus = <3500>;
		oplus_spec,voocphy_vooc_cp_max_ibus = <3500>;
		oplus_spec,batt_pwd_curr_thd1 = <3800>;
		oplus_spec,batt_pwd_vol_thd1 = <4605>;

		oplus_spec,voocphy_freq_mincore = <940800>;
		oplus_spec,voocphy_freq_midcore = <1440000>;
		oplus_spec,voocphy_freq_maxcore = <1538000>;
		oplus_spec,voocphy_current_change_timeout = <100>;
		oplus_spec,copycat_vooc_support;

		oplus,abnormal_adapter_current = <CURR_LIMIT_7BIT_9_5A CURR_LIMIT_7BIT_9_5A
						  CURR_LIMIT_7BIT_5_0A CURR_LIMIT_7BIT_5_0A
						  CURR_LIMIT_7BIT_4_0A CURR_LIMIT_7BIT_4_0A
						  CURR_LIMIT_7BIT_3_0A CURR_LIMIT_7BIT_3_0A
						  CURR_LIMIT_7BIT_2_0A CURR_LIMIT_7BIT_2_0A>;

		oplus_spec,soc_range = <0 20 35 55 75 85 95>;

		svooc_batt_sys_curve = <1 0 1 1 0 1 1	// 9100mA
					1 0 1 1 1 0 0	// 4324mV
					0 0 1 0 1 0 0	// 2000mA
					1 1 1 0 1 1 1	// 4594mV
					0 0 0 1 1 0 0	// 1200mA
					1 1 1 0 1 1 1>; // 4594mV

		vooc_batt_sys_curve =  <0 1 0 1 1 0 1 	// 4500mA
					0 0 0 0 0 0 1	// 3414mV
					0 0 1 0 1 0 0	// 2000mA
					1 1 1 0 1 1 1	// 4594mV
					0 0 0 1 0 1 0	// 1000mA
					1 1 1 0 1 1 1>; // 4594mV

		svooc_lcf_strategy {
			oplus,temp_type = <OPLUS_STRATEGY_USE_SHELL_TEMP>;
			oplus,temp_range = <0 50 120 160 210 380 440>;

			strategy_temp_range_curves {
				strategy_temp_range_t0 =	<460 4570 0
								 435 4560 0
								 410 4550 0
								 385 4540 0
								 360 4530 1>;
				strategy_temp_range_t1 =	<550 4570 0
								 515 4565 0
								 480 4550 0
								 445 4540 0
								 410 4530 1>;
				strategy_temp_range_t2 =	<700 4570 0
								 655 4565 0
								 610 4550 0
								 565 4540 0
								 520 4530 1>;
				strategy_temp_range_t3 =	<800 4570 0
								 750 4565 0
								 650 4550 0
								 550 4540 0
								 400 4530 1>;
				strategy_temp_range_t4 =	<1300 4570 0
								 1250 4565 0
								 1150 4550 0
								 1050 4540 0
								 900 4530 1>;
				strategy_temp_range_t5 =	<2200 4570 0
								 2150 4565 0
								 2050 4550 0
								 1950 4540 0
								 1800 4530 1>;
			};
		};

		svooc_charge_strategy {
			strategy_soc_0_to_50 { /* 0 ~ 20 */
				strategy_temp_little_cold =	<4150 13 0 0 0
								4150 10 0 0 0
								4570  5 1 0 0>;
				strategy_temp_cool =		<4150 21 0 0 0
								4150 20 0 0 0
								4150 15 0 0 0
								4510 13 0 0 0
								4510 10 0 0 0
								4560  7 0 0 0
								4570  6 1 0 0>;
				strategy_temp_little_cool =	<4150 27 0 0 0
								4150 25 0 0 0
								4330 21 0 0 0
								4330 20 0 0 0
								4330 15 0 0 0
								4560 13 0 0 0
								4560 10 0 0 0
								4570  7 1 0 0>;
				strategy_temp_little_cool_high =	<4150 55 0 1200 0
								4150 50 0 600 0
								4150 45 0 600 0
								4280 41 0 600 0
								4280 40 0 0 0
								4280 35 0 0 0
								4510 33 0 0 0
								4510 30 0 0 0
								4560 27 0 0 0
								4560 25 0 0 0
								4560 20 0 0 0
								4560 15 0 0 0
								4560 10 0 0 0
								4570  9 1 0 0>;
				strategy_temp_normal_low =	<4110 91 0 240 0
								4110 90 0 240 0
								4110 85 0 360 0
								4220 80 0 360 0
								4220 75 0 360 0
								4220 70 0 600 0
								4370 68 0 600 0
								4370 65 0 600 0
								4370 60 0 1200 0
								4370 55 0 1200 0
								4470 53 0 600 0
								4470 50 0 600 0
								4470 45 0 600 0
								4470 40 0 0 0
								4520 39 0 0 0
								4520 35 0 0 0
								4560 31 0 0 0
								4560 30 0 0 0
								4560 25 0 0 0
								4560 20 0 0 0
								4560 15 0 0 0
								4570 14 1 0 0>;
				strategy_temp_normal_high =	<4110 91 0 240 0
								4110 90 0 240 0
								4110 85 0 360 0
								4220 80 0 360 0
								4220 75 0 360 0
								4220 70 0 600 0
								4370 68 0 600 0
								4370 65 0 600 0
								4370 60 0 1200 0
								4370 55 0 1200 0
								4470 53 0 1200 0
								4470 50 0 600 0
								4470 45 0 600 0
								4470 40 0 0 0
								4520 39 0 0 0
								4520 35 0 0 0
								4560 31 0 0 0
								4560 30 0 0 0
								4560 25 0 0 0
								4570 23 1 0 0>;
				strategy_temp_warm =		<4120 15 0 0 0
								4120 10 0 0 0
								4130  5 1 0 0>;
			};

			strategy_soc_0_to_50_mid { /* 21 ~ 35 */
				strategy_temp_little_cold =	<4150 13 0 0 0
								4150 10 0 0 0
								4570  5 1 0 0>;
				strategy_temp_cool =		<4150 21 0 0 0
								4150 20 0 0 0
								4150 15 0 0 0
								4510 13 0 0 0
								4510 10 0 0 0
								4560  7 0 0 0
								4570  6 1 0 0>;
				strategy_temp_little_cool =	<4150 27 0 0 0
								4150 25 0 0 0
								4330 21 0 0 0
								4330 20 0 0 0
								4330 15 0 0 0
								4560 13 0 0 0
								4560 10 0 0 0
								4570  7 1 0 0>;
				strategy_temp_little_cool_high =	<4150 55 0 1200 0
								4150 50 0 600 0
								4150 45 0 600 0
								4280 41 0 600 0
								4280 40 0 0 0
								4280 35 0 0 0
								4510 33 0 0 0
								4510 30 0 0 0
								4560 27 0 0 0
								4560 25 0 0 0
								4560 20 0 0 0
								4560 15 0 0 0
								4560 10 0 0 0
								4570  9 1 0 0>;
				strategy_temp_normal_low =	<4110 91 0 240 0
								4110 90 0 240 0
								4110 85 0 360 0
								4220 80 0 360 0
								4220 75 0 360 0
								4220 70 0 600 0
								4370 68 0 600 0
								4370 65 0 600 0
								4370 60 0 1200 0
								4370 55 0 1200 0
								4470 53 0 600 0
								4470 50 0 600 0
								4470 45 0 600 0
								4470 40 0 0 0
								4520 39 0 0 0
								4520 35 0 0 0
								4560 31 0 0 0
								4560 30 0 0 0
								4560 25 0 0 0
								4560 20 0 0 0
								4560 15 0 0 0
								4570 14 1 0 0>;
				strategy_temp_normal_high =	<4110 91 0 240 0
								4110 90 0 240 0
								4110 85 0 360 0
								4220 80 0 360 0
								4220 75 0 360 0
								4220 70 0 600 0
								4370 68 0 600 0
								4370 65 0 600 0
								4370 60 0 1200 0
								4370 55 0 1200 0
								4470 53 0 1200 0
								4470 50 0 600 0
								4470 45 0 600 0
								4470 40 0 0 0
								4520 39 0 0 0
								4520 35 0 0 0
								4560 31 0 0 0
								4560 30 0 0 0
								4560 25 0 0 0
								4570 23 1 0 0>;
				strategy_temp_warm =		<4120 15 0 0 0
								4120 10 0 0 0
								4130  5 1 0 0>;
			};

			strategy_soc_0_to_50_high { /* 36 ~ 55 */
				strategy_temp_little_cold =	<4150 10 0 0 0
								4570  5 1 0 0>;
				strategy_temp_cool =		<4150 20 0 0 0
								4150 15 0 0 0
								4510 13 0 0 0
								4510 10 0 0 0
								4560  7 0 0 0
								4570  6 1 0 0>;
				strategy_temp_little_cool =	<4150 27 0 0 0
								4150 25 0 0 0
								4330 21 0 0 0
								4330 20 0 0 0
								4330 15 0 0 0
								4560 13 0 0 0
								4560 10 0 0 0
								4570  7 1 0 0>;
				strategy_temp_little_cool_high =	<4150 55 0 1200 0
								4150 50 0 600 0
								4150 45 0 600 0
								4280 41 0 600 0
								4280 40 0 0 0
								4280 35 0 0 0
								4510 33 0 0 0
								4510 30 0 0 0
								4560 27 0 0 0
								4560 25 0 0 0
								4560 20 0 0 0
								4560 15 0 0 0
								4560 10 0 0 0
								4570  9 1 0 0>;
				strategy_temp_normal_low =	<4110 91 0 240 0
								4110 90 0 240 0
								4110 85 0 360 0
								4220 80 0 360 0
								4220 75 0 360 0
								4220 70 0 600 0
								4370 68 0 600 0
								4370 65 0 600 0
								4370 60 0 1200 0
								4370 55 0 1200 0
								4470 53 0 600 0
								4470 50 0 600 0
								4470 45 0 600 0
								4470 40 0 0 0
								4520 39 0 0 0
								4520 35 0 0 0
								4560 31 0 0 0
								4560 30 0 0 0
								4560 25 0 0 0
								4560 20 0 0 0
								4560 15 0 0 0
								4570 14 1 0 0>;
				strategy_temp_normal_high =	<4110 91 0 240 0
								4110 90 0 240 0
								4110 85 0 360 0
								4220 80 0 360 0
								4220 75 0 360 0
								4220 70 0 600 0
								4370 68 0 600 0
								4370 65 0 600 0
								4370 60 0 1200 0
								4370 55 0 1200 0
								4470 53 0 1200 0
								4470 50 0 600 0
								4470 45 0 600 0
								4470 40 0 0 0
								4520 39 0 0 0
								4520 35 0 0 0
								4560 31 0 0 0
								4560 30 0 0 0
								4560 25 0 0 0
								4570 23 1 0 0>;
				strategy_temp_warm =		<4120 15 0 0 0
								4120 10 0 0 0
								4130  5 1 0 0>;
			};

			strategy_soc_50_to_75 { /* 56 ~ 75 */
				strategy_temp_little_cold =	<4150 10 0 0 0
								4570  5 1 0 0>;
				strategy_temp_cool =		<4150 20 0 0 0
								4150 15 0 0 0
								4510 13 0 0 0
								4510 10 0 0 0
								4560  7 0 0 0
								4570  6 1 0 0>;
				strategy_temp_little_cool =	<4150 27 0 0 0
								4150 25 0 0 0
								4330 21 0 0 0
								4330 20 0 0 0
								4330 15 0 0 0
								4560 13 0 0 0
								4560 10 0 0 0
								4570  7 1 0 0>;
				strategy_temp_little_cool_high =	<4280 40 0 0 0
								4280 35 0 0 0
								4510 33 0 0 0
								4510 30 0 0 0
								4560 27 0 0 0
								4560 25 0 0 0
								4560 20 0 0 0
								4560 15 0 0 0
								4560 10 0 0 0
								4570  9 1 0 0>;
				strategy_temp_normal_low =	<4470 45 0 600 0
								4470 40 0 0 0
								4520 39 0 0 0
								4520 35 0 0 0
								4560 31 0 0 0
								4560 30 0 0 0
								4560 25 0 0 0
								4560 20 0 0 0
								4560 15 0 0 0
								4570 14 1 0 0>;
				strategy_temp_normal_high =	<4470 50 0 600 0
								4470 45 0 600 0
								4470 40 0 0 0
								4520 39 0 0 0
								4520 35 0 0 0
								4560 31 0 0 0
								4560 30 0 0 0
								4560 25 0 0 0
								4570 23 1 0 0>;
			};

			strategy_soc_75_to_85 { /* 76 ~ 85 */
				strategy_temp_little_cold =	<4150 10 0 0 0
								4570  5 1 0 0>;
				strategy_temp_cool =		<4150 20 0 0 0
								4150 15 0 0 0
								4510 13 0 0 0
								4510 10 0 0 0
								4560  7 0 0 0
								4570  6 1 0 0>;
				strategy_temp_little_cool =	<4150 27 0 0 0
								4150 25 0 0 0
								4330 21 0 0 0
								4330 20 0 0 0
								4330 15 0 0 0
								4560 13 0 0 0
								4560 10 0 0 0
								4570  7 1 0 0>;
				strategy_temp_little_cool_high =	<4510 30 0 0 0
								4560 27 0 0 0
								4560 25 0 0 0
								4560 20 0 0 0
								4560 15 0 0 0
								4560 10 0 0 0
								4570  9 1 0 0>;
				strategy_temp_normal_low =	<4520 35 0 0 0
								4560 31 0 0 0
								4560 30 0 0 0
								4560 25 0 0 0
								4560 20 0 0 0
								4560 15 0 0 0
								4570 14 1 0 0>;
				strategy_temp_normal_high =	<4520 35 0 0 0
								4560 31 0 0 0
								4560 30 0 0 0
								4560 25 0 0 0
								4570 23 1 0 0>;
			};

			strategy_soc_85_to_90 { /* 86 ~ 95 */
				strategy_temp_little_cold =	<4150 10 0 0 0
								4570  5 1 0 0>;
				strategy_temp_cool =		<4150 15 0 0 0
								4510 13 0 0 0
								4510 10 0 0 0
								4560  7 0 0 0
								4570  6 1 0 0>;
				strategy_temp_little_cool =	<4330 15 0 0 0
								4560 13 0 0 0
								4560 10 0 0 0
								4570  7 1 0 0>;
				strategy_temp_little_cool_high =	<4560 15 0 0 0
								4560 10 0 0 0
								4570  9 1 0 0>;
				strategy_temp_normal_low =	<4560 20 0 0 0
								4560 15 0 0 0
								4570 14 1 0 0>;
				strategy_temp_normal_high =	<4570 23 1 0 0>;
			};
		};

		vooc_charge_strategy {
			strategy_soc_0_to_50 {
				strategy_temp_little_cold =	<4430 20 1 0 0>;
				strategy_temp_cool =		<4420 30 0 0 0
								 4430 20 1 0 0>;
				strategy_temp_little_cool =	<4475 30 0 0 0
								 4480 20 1 0 0>;
				strategy_temp_little_cool_high =	<4475 30 0 0 0
								 4480 20 1 0 0>;
				strategy_temp_normal_low =	<4475 30 0 0 0
								 4480 20 1 0 0>;
				strategy_temp_normal_high =	<4475 30 0 0 0
								 4480 20 1 0 0>;
				strategy_temp_warm =		<4130 24 1 0 0>;
			};

			strategy_soc_0_to_50_mid {
				strategy_temp_little_cold =	<4430 20 1 0 0>;
				strategy_temp_cool =		<4420 30 0 0 0
								 4430 20 1 0 0>;
				strategy_temp_little_cool =	<4475 30 0 0 0
								 4480 20 1 0 0>;
				strategy_temp_little_cool_high =	<4475 30 0 0 0
								 4480 20 1 0 0>;
				strategy_temp_normal_low =	<4475 30 0 0 0
								 4480 20 1 0 0>;
				strategy_temp_normal_high =	<4475 30 0 0 0
								 4480 20 1 0 0>;
				strategy_temp_warm =		<4130 24 1 0 0>;
			};

			strategy_soc_0_to_50_high {
				strategy_temp_little_cold =	<4430 20 1 0 0>;
				strategy_temp_cool =		<4420 30 0 0 0
								 4430 20 1 0 0>;
				strategy_temp_little_cool =	<4475 30 0 0 0
								 4480 20 1 0 0>;
				strategy_temp_little_cool_high =	<4475 30 0 0 0
								 4480 20 1 0 0>;
				strategy_temp_normal_low =	<4475 30 0 0 0
								 4480 20 1 0 0>;
				strategy_temp_normal_high =	<4475 30 0 0 0
								 4480 20 1 0 0>;
				strategy_temp_warm =		<4130 24 1 0 0>;
			};

			strategy_soc_50_to_75 {
				strategy_temp_little_cold =	<4430 20 1 0 0>;
				strategy_temp_cool =		<4420 30 0 0 0
								 4430 20 1 0 0>;
				strategy_temp_little_cool =	<4475 30 0 0 0
								 4480 20 1 0 0>;
				strategy_temp_little_cool_high =	<4475 30 0 0 0
								 4480 20 1 0 0>;
				strategy_temp_normal_low =	<4475 30 0 0 0
								 4480 20 1 0 0>;
				strategy_temp_normal_high =	<4475 30 0 0 0
								 4480 20 1 0 0>;
				strategy_temp_warm =		<4130 24 1 0 0>;
			};

			strategy_soc_75_to_85 {
				strategy_temp_little_cold =	<4430 20 1 0 0>;
				strategy_temp_cool =		<4430 20 1 0 0>;
				strategy_temp_little_cool =	<4480 20 1 0 0>;
				strategy_temp_little_cool_high =	<4480 20 1 0 0>;
				strategy_temp_normal_low =	<4475 30 0 0 0
								 4480 20 1 0 0>;
				strategy_temp_normal_high =	<4475 30 0 0 0
								 4480 20 1 0 0>;
				strategy_temp_warm =		<4130 24 1 0 0>;
			};

			strategy_soc_85_to_90 {
				strategy_temp_little_cold =	<4430 20 1 0 0>;
				strategy_temp_cool =		<4430 20 1 0 0>;
				strategy_temp_little_cool =	<4480 20 1 0 0>;
				strategy_temp_little_cool_high =	<4480 20 1 0 0>;
				strategy_temp_normal_low =	<4480 20 1 0 0>;
				strategy_temp_normal_high =	<4480 20 1 0 0>;
				strategy_temp_warm =		<4130 24 1 0 0>;
			};
		};
		oplus_sc8517_cp: oplus,sc8517_cp {
			oplus,ic_type = <OPLUS_CHG_IC_CP>;
			oplus,ic_index = <0>;
		};
	};
};
//#endif OPLUS_FEATURE_CHG_BASIC /*for wired charging config*/
//#endif OPLUS_FEATURE_CHG_BASIC /*for wired charging config*/

//for ufcs config
&soc {
	oplus_cpa: oplus,cpa {
		compatible = "oplus,cpa";
		/* format: <protocol_type power_w> */
		oplus,protocol_list = <CHG_PROTOCOL_UFCS 100
				       CHG_PROTOCOL_PD   18
				       CHG_PROTOCOL_VOOC 100
				       CHG_PROTOCOL_QC   18>;
		oplus,default_protocol_list = <CHG_PROTOCOL_UFCS
					       CHG_PROTOCOL_PD
					       CHG_PROTOCOL_VOOC>;
	};

	oplus_ufcs_virtual_cp: oplus,ufcs_virtual_cp {
		compatible = "oplus,virtual_cp";

		oplus,ic_type = <OPLUS_CHG_IC_VIRTUAL_CP>;
		oplus,ic_index = <1>;

		oplus,cp_ic = <&oplus_sc8517_cp &oplus_adsp_mos>;
		oplus,input_curr_max_ma = <13700 0>;

		oplus,cp_ic_connect = <OPLUS_CHG_IC_CONNECT_PARALLEL>;
		oplus,main_cp = <0>;
	};

	oplus_virtual_platufcs: oplus,virtual_platufcs {
		compatible = "oplus,virtual_platufcs";

		oplus,ufcs_ic = <&oplus_adsp_ufcs>;
		oplus,ufcs_ic_index = <0>;
		oplus,ufcs_ic_connect = <OPLUS_CHG_IC_CONNECT_PARALLEL>;

		oplus,ufcs_ic_func_group = <&adsp_ufcs_groups>;
		oplus,ic_type = <OPLUS_CHG_IC_VIRTUAL_UFCS>;
		oplus,ic_index = <0>;
	};

	oplus_ufcs_charge: oplus,ufcs_charge {
		compatible = "oplus,ufcs_charge";
		oplus,ufcs_ic = <&oplus_virtual_platufcs>;
		oplus,cp_ic = <&oplus_ufcs_virtual_cp>;
		oplus,dpdm_switch_ic = <&oplus_adsp_dpdm_switch>;

		oplus,adsp_ufcs_project;
		oplus,ufcs_boot_time_retry = <10>;
		oplus,impedance_unit = <&oplus_ufcs_impedance_unit>;
		oplus,ufcs_need_reset_adapter;

		oplus,target_vbus_mv = <11000>;
		oplus,curr_max_ma = <9100>;
		oplus,subboard_ntc_abnormal_current = <7300>;
		oplus,ufcs_warm_allow_vol = <4000>;
		oplus,ufcs_warm_allow_soc = <55>;
		oplus,ufcs_strategy_normal_current = <9100>;
		oplus,ufcs_over_high_or_low_current = <9100>;
		oplus,ufcs_timeout_third = <14888>;
		oplus,ufcs_timeout_oplus = <14888>;
		oplus,ufcs_ibat_over_third = <5400>;
		oplus,ufcs_ibat_over_oplus = <10500>;
		oplus,ufcs_ibus_over_oplus = <11000>;
		oplus,ufcs_full_cool_sw_vbat = <4600>;
		oplus,ufcs_full_normal_sw_vbat = <4600>;
		oplus,ufcs_full_normal_hw_vbat = <4610>;
		oplus,ufcs_full_ffc_vbat = <4540>;
		oplus,ufcs_full_warm_vbat = <4130>;
		oplus,ufcs_full_cool_sw_vbat_third = <4500>;
		oplus,ufcs_full_normal_sw_vbat_third= <4500>;
		oplus,ufcs_full_normal_hw_vbat_third = <4540>;
		oplus,ufcs_current_change_timeout = <100>;
		oplus,ufcs_strategy_batt_high_temp = <400 420 430 390 410 420>;
		oplus,ufcs_strategy_high_current = <6000 5000 3000 9100 6000 5000>;
		oplus,ufcs_little_cool_high_temp = <210>;
		oplus,curve_strategy_name = "pps_ufcs_curve_v2";
		oplus_spec,ufcs_low_temp = <50>;
		oplus_spec,ufcs_high_soc = <95>;
		oplus,ufcs_charge_strategy_soc = <0 20 35 55 75 85 95>;
		oplus,ufcs_charge_strategy_temp = <0 50 120 160 350 440 510>;

		oplus,plc_strategy-data = <&oplus_ufcs_step_strategy &cp_2t1_simple_strategy>;
		oplus,plc_strategy-names = "default", "third";

		ufcs_oplus_lcf_strategy {
			oplus,temp_type = <OPLUS_STRATEGY_USE_SHELL_TEMP>;
			oplus,temp_range = <0 50 120 160 210 380 440>;

			strategy_temp_range_curves {
				strategy_temp_range_t0 =	<460 4570 0
								 435 4560 0
								 410 4550 0
								 385 4540 0
								 360 4530 1>;
				strategy_temp_range_t1 =	<550 4570 0
								 515 4565 0
								 480 4550 0
								 445 4540 0
								 410 4530 1>;
				strategy_temp_range_t2 =	<700 4570 0
								 655 4565 0
								 610 4550 0
								 565 4540 0
								 520 4530 1>;
				strategy_temp_range_t3 =	<800 4570 0
								 750 4565 0
								 650 4550 0
								 550 4540 0
								 400 4530 1>;
				strategy_temp_range_t4 =	<1300 4570 0
								 1250 4565 0
								 1150 4550 0
								 1050 4540 0
								 900 4530 1>;
				strategy_temp_range_t5 =	<2200 4570 0
								 2150 4565 0
								 2050 4550 0
								 1950 4540 0
								 1800 4530 1>;
			};
		};

		ufcs_third_lcf_strategy {
			oplus,temp_type = <OPLUS_STRATEGY_USE_SHELL_TEMP>;
			oplus,temp_range = <0 50 120 160 210 380 440>;

			strategy_temp_range_curves {
				strategy_temp_range_t0 =	<460 4570 0
								 435 4560 0
								 410 4550 0
								 385 4540 0
								 360 4530 1>;
				strategy_temp_range_t1 =	<550 4570 0
								 515 4565 0
								 480 4550 0
								 445 4540 0
								 410 4530 1>;
				strategy_temp_range_t2 =	<700 4570 0
								 655 4565 0
								 610 4550 0
								 565 4540 0
								 520 4530 1>;
				strategy_temp_range_t3 =	<800 4570 0
								 750 4565 0
								 650 4550 0
								 550 4540 0
								 400 4530 1>;
				strategy_temp_range_t4 =	<1300 4570 0
								 1250 4565 0
								 1150 4550 0
								 1050 4540 0
								 900 4530 1>;
				strategy_temp_range_t5 =	<2200 4570 0
								 2150 4565 0
								 2050 4550 0
								 1950 4540 0
								 1800 4530 1>;
			};
		};

		ufcs_charge_third_strategy {
			oplus,temp_type = <OPLUS_STRATEGY_USE_SHELL_TEMP>;
			oplus,soc_range = <0 20 35 55 75 85 95>;
			oplus,temp_range = <0 50 120 160 210 350 440 510>;

			strategy_soc_range_min {
				strategy_temp_little_cold =	<11000 4140 1300 0 0
								11000 4150 1000 1 0>;
				strategy_temp_cool =		<11000 4150 2100 0 0
								11000 4150 2000 0 0
								11000 4150 1500 0 0
								11000 4490 1300 0 0
								11000 4500 1000 1 0>;
				strategy_temp_little_cool =	<11000 4150 2700 0 0
								11000 4150 2500 0 0
								11000 4330 2100 0 0
								11000 4330 2000 0 0
								11000 4330 1500 0 0
								11000 4490 1300 0 0
								11000 4500 1000 1 0>;
				strategy_temp_little_cool_high = <11000 4490 3000 0 0
								11000 4490 2700 0 0
								11000 4490 2500 0 0
								11000 4490 2000 0 0
								11000 4490 1500 0 0
								11000 4500 1000 1 0>;
				strategy_temp_normal_low =	<11000 4490 3000 0 0
								11000 4490 2500 0 0
								11000 4490 2000 0 0
								11000 4490 1500 0 0
								11000 4500 1000 1 0>;
				strategy_temp_normal_high =	<11000 4465 3000 0 0
								11000 4465 2500 0 0
								11000 4465 2000 0 0
								11000 4465 1500 0 0
								11000 4475 1000 1 0>;
				strategy_temp_warm =		<11000 4120 1500 0 0
								11000 4130 1000 1 0>;
			};
			strategy_soc_range_low {
				strategy_temp_little_cold =	<11000 4140 1300 0 0
								11000 4150 1000 1 0>;
				strategy_temp_cool =		<11000 4150 2100 0 0
								11000 4150 2000 0 0
								11000 4150 1500 0 0
								11000 4490 1300 0 0
								11000 4500 1000 1 0>;
				strategy_temp_little_cool =	<11000 4150 2700 0 0
								11000 4150 2500 0 0
								11000 4330 2100 0 0
								11000 4330 2000 0 0
								11000 4330 1500 0 0
								11000 4490 1300 0 0
								11000 4500 1000 1 0>;
				strategy_temp_little_cool_high = <11000 4490 3000 0 0
								11000 4490 2700 0 0
								11000 4490 2500 0 0
								11000 4490 2000 0 0
								11000 4490 1500 0 0
								11000 4500 1000 1 0>;
				strategy_temp_normal_low =	<11000 4490 3000 0 0
								11000 4490 2500 0 0
								11000 4490 2000 0 0
								11000 4490 1500 0 0
								11000 4500 1000 1 0>;
				strategy_temp_normal_high =	<11000 4465 3000 0 0
								11000 4465 2500 0 0
								11000 4465 2000 0 0
								11000 4465 1500 0 0
								11000 4475 1000 1 0>;
				strategy_temp_warm =		<11000 4120 1500 0 0
								11000 4130 1000 1 0>;
			};
			strategy_soc_range_mid_low {
				strategy_temp_little_cold =	<11000 4140 1300 0 0
								11000 4150 1000 1 0>;
				strategy_temp_cool =		<11000 4150 2100 0 0
								11000 4150 2000 0 0
								11000 4150 1500 0 0
								11000 4490 1300 0 0
								11000 4500 1000 1 0>;
				strategy_temp_little_cool =	<11000 4150 2700 0 0
								11000 4150 2500 0 0
								11000 4330 2100 0 0
								11000 4330 2000 0 0
								11000 4330 1500 0 0
								11000 4490 1300 0 0
								11000 4500 1000 1 0>;
				strategy_temp_little_cool_high = <11000 4490 3000 0 0
								11000 4490 2700 0 0
								11000 4490 2500 0 0
								11000 4490 2000 0 0
								11000 4490 1500 0 0
								11000 4500 1000 1 0>;
				strategy_temp_normal_low =	<11000 4490 3000 0 0
								11000 4490 2500 0 0
								11000 4490 2000 0 0
								11000 4490 1500 0 0
								11000 4500 1000 1 0>;
				strategy_temp_normal_high =	<11000 4465 3000 0 0
								11000 4465 2500 0 0
								11000 4465 2000 0 0
								11000 4465 1500 0 0
								11000 4475 1000 1 0>;
				strategy_temp_warm =		<11000 4120 1500 0 0
								11000 4130 1000 1 0>;
			};
			strategy_soc_range_mid {
				strategy_temp_little_cold =	<11000 4140 1300 0 0
								11000 4150 1000 1 0>;
				strategy_temp_cool =		<11000 4150 2000 0 0
								11000 4150 1500 0 0
								11000 4490 1300 0 0
								11000 4500 1000 1 0>;
				strategy_temp_little_cool =	<11000 4150 2700 0 0
								11000 4150 2500 0 0
								11000 4330 2100 0 0
								11000 4330 2000 0 0
								11000 4330 1500 0 0
								11000 4490 1300 0 0
								11000 4500 1000 1 0>;
				strategy_temp_little_cool_high = <11000 4490 3000 0 0
								11000 4490 2700 0 0
								11000 4490 2500 0 0
								11000 4490 2000 0 0
								11000 4490 1500 0 0
								11000 4500 1000 1 0>;
				strategy_temp_normal_low =	<11000 4490 3000 0 0
								11000 4490 2500 0 0
								11000 4490 2000 0 0
								11000 4490 1500 0 0
								11000 4500 1000 1 0>;
				strategy_temp_normal_high =	<11000 4465 3000 0 0
								11000 4465 2500 0 0
								11000 4465 2000 0 0
								11000 4465 1500 0 0
								11000 4475 1000 1 0>;
				strategy_temp_warm =		<11000 4130 1000 1 0>;
			};
			strategy_soc_range_mid_high {
				strategy_temp_little_cold =	<11000 4150 1000 1 0>;
				strategy_temp_cool =		<11000 4150 1500 0 0
								11000 4490 1300 0 0
								11000 4500 1000 1 0>;
				strategy_temp_little_cool =	<11000 4330 2000 0 0
								11000 4330 1500 0 0
								11000 4490 1300 0 0
								11000 4500 1000 1 0>;
				strategy_temp_little_cool_high = <11000 4490 2000 0 0
								11000 4490 1500 0 0
								11000 4500 1000 1 0>;
				strategy_temp_normal_low =	<11000 4490 2500 0 0
								11000 4490 2000 0 0
								11000 4490 1500 0 0
								11000 4500 1000 1 0>;
				strategy_temp_normal_high =	<11000 4465 2500 0 0
								11000 4465 2000 0 0
								11000 4465 1500 0 0
								11000 4475 1000 1 0>;
				strategy_temp_warm =		<11000 4130 1000 1 0>;
			};
			strategy_soc_range_high {
				strategy_temp_little_cold =	<11000 4150 1000 1 0>;
				strategy_temp_cool =		<11000 4500 1000 1 0>;
				strategy_temp_little_cool =	<11000 4500 1000 1 0>;
				strategy_temp_little_cool_high = <11000 4500 1000 1 0>;
				strategy_temp_normal_low =	<11000 4500 1000 1 0>;
				strategy_temp_normal_high =	<11000 4475 1000 1 0>;
				strategy_temp_warm =		<11000 4130 1000 1 0>;
			};
		};

		ufcs_charge_oplus_strategy {
			oplus,temp_type = <OPLUS_STRATEGY_USE_SHELL_TEMP>;
			oplus,soc_range = <0 20 35 55 75 85 95>;
			oplus,temp_range = <0 50 120 160 210 350 440 510>;

			strategy_soc_range_min {
				strategy_temp_little_cold =	<11000 4150 1300 0 0
								11000 4150 1000 0 0
								11000 4570 500 1 0>;
				strategy_temp_cool =		<11000 4150 2100 0 0
								11000 4150 2000 0 0
								11000 4150 1500 0 0
								11000 4510 1300 0 0
								11000 4510 1000 0 0
								11000 4560 700 0 0
								11000 4570 600 1 0>;
				strategy_temp_little_cool =	<11000 4150 2700 0 0
								11000 4150 2500 0 0
								11000 4330 2100 0 0
								11000 4330 2000 0 0
								11000 4330 1500 0 0
								11000 4560 1300 0 0
								11000 4560 1000 0 0
								11000 4570 700 1 0>;
				strategy_temp_little_cool_high = <11000 4150 5500 0 0
								11000 4150 5000 0 0
								11000 4150 4500 0 0
								11000 4280 4100 0 0
								11000 4280 4000 0 0
								11000 4280 3500 0 0
								11000 4510 3300 0 0
								11000 4510 3000 0 0
								11000 4560 2700 0 0
								11000 4560 2500 0 0
								11000 4560 2000 0 0
								11000 4560 1500 0 0
								11000 4560 1000 0 0
								11000 4570 900 1 0>;
				strategy_temp_normal_low =	<11000 4110 9100 0 0
								11000 4110 9000 0 0
								11000 4110 8500 0 0
								11000 4220 8000 0 0
								11000 4220 7500 0 0
								11000 4220 7000 0 0
								11000 4370 6800 0 0
								11000 4370 6500 0 0
								11000 4370 6000 0 0
								11000 4370 5500 0 0
								11000 4470 5300 0 0
								11000 4470 5000 0 0
								11000 4470 4500 0 0
								11000 4470 4000 0 0
								11000 4520 3900 0 0
								11000 4520 3500 0 0
								11000 4560 3100 0 0
								11000 4560 3000 0 0
								11000 4560 2500 0 0
								11000 4560 2000 0 0
								11000 4560 1500 0 0
								11000 4570 1400 1 0>;
				strategy_temp_normal_high =	<11000 4110 9100 0 0
								11000 4110 9000 0 0
								11000 4110 8500 0 0
								11000 4220 8000 0 0
								11000 4220 7500 0 0
								11000 4220 7000 0 0
								11000 4370 6800 0 0
								11000 4370 6500 0 0
								11000 4370 6000 0 0
								11000 4370 5500 0 0
								11000 4470 5300 0 0
								11000 4470 5000 0 0
								11000 4470 4500 0 0
								11000 4470 4000 0 0
								11000 4520 3900 0 0
								11000 4520 3500 0 0
								11000 4560 3100 0 0
								11000 4560 3000 0 0
								11000 4560 2500 0 0
								11000 4570 2300 1 0>;
				strategy_temp_warm =		<11000 4120 1500 0 0
								11000 4120 1000 0 0
								11000 4130 500 1 0>;
			};
			strategy_soc_range_low {
				strategy_temp_little_cold =	<11000 4150 1300 0 0
								11000 4150 1000 0 0
								11000 4570 500 1 0>;
				strategy_temp_cool =		<11000 4150 2100 0 0
								11000 4150 2000 0 0
								11000 4150 1500 0 0
								11000 4510 1300 0 0
								11000 4510 1000 0 0
								11000 4560 700 0 0
								11000 4570 600 1 0>;
				strategy_temp_little_cool =	<11000 4150 2700 0 0
								11000 4150 2500 0 0
								11000 4330 2100 0 0
								11000 4330 2000 0 0
								11000 4330 1500 0 0
								11000 4560 1300 0 0
								11000 4560 1000 0 0
								11000 4570 700 1 0>;
				strategy_temp_little_cool_high = <11000 4150 5500 0 0
								11000 4150 5000 0 0
								11000 4150 4500 0 0
								11000 4280 4100 0 0
								11000 4280 4000 0 0
								11000 4280 3500 0 0
								11000 4510 3300 0 0
								11000 4510 3000 0 0
								11000 4560 2700 0 0
								11000 4560 2500 0 0
								11000 4560 2000 0 0
								11000 4560 1500 0 0
								11000 4560 1000 0 0
								11000 4570 900 1 0>;
				strategy_temp_normal_low =	<11000 4110 9100 0 0
								11000 4110 9000 0 0
								11000 4110 8500 0 0
								11000 4220 8000 0 0
								11000 4220 7500 0 0
								11000 4220 7000 0 0
								11000 4370 6800 0 0
								11000 4370 6500 0 0
								11000 4370 6000 0 0
								11000 4370 5500 0 0
								11000 4470 5300 0 0
								11000 4470 5000 0 0
								11000 4470 4500 0 0
								11000 4470 4000 0 0
								11000 4520 3900 0 0
								11000 4520 3500 0 0
								11000 4560 3100 0 0
								11000 4560 3000 0 0
								11000 4560 2500 0 0
								11000 4560 2000 0 0
								11000 4560 1500 0 0
								11000 4570 1400 1 0>;
				strategy_temp_normal_high =	<11000 4110 9100 0 0
								11000 4110 9000 0 0
								11000 4110 8500 0 0
								11000 4220 8000 0 0
								11000 4220 7500 0 0
								11000 4220 7000 0 0
								11000 4370 6800 0 0
								11000 4370 6500 0 0
								11000 4370 6000 0 0
								11000 4370 5500 0 0
								11000 4470 5300 0 0
								11000 4470 5000 0 0
								11000 4470 4500 0 0
								11000 4470 4000 0 0
								11000 4520 3900 0 0
								11000 4520 3500 0 0
								11000 4560 3100 0 0
								11000 4560 3000 0 0
								11000 4560 2500 0 0
								11000 4570 2300 1 0>;
				strategy_temp_warm =		<11000 4120 1500 0 0
								11000 4120 1000 0 0
								11000 4130 500 1 0>;
			};
			strategy_soc_range_mid_low {
				strategy_temp_little_cold =	<11000 4150 1000 0 0
								11000 4570 500 1 0>;
				strategy_temp_cool =		<11000 4150 2000 0 0
								11000 4150 1500 0 0
								11000 4510 1300 0 0
								11000 4510 1000 0 0
								11000 4560 700 0 0
								11000 4570 600 1 0>;
				strategy_temp_little_cool =	<11000 4150 2700 0 0
								11000 4150 2500 0 0
								11000 4330 2100 0 0
								11000 4330 2000 0 0
								11000 4330 1500 0 0
								11000 4560 1300 0 0
								11000 4560 1000 0 0
								11000 4570 700 1 0>;
				strategy_temp_little_cool_high = <11000 4150 5500 0 0
								11000 4150 5000 0 0
								11000 4150 4500 0 0
								11000 4280 4100 0 0
								11000 4280 4000 0 0
								11000 4280 3500 0 0
								11000 4510 3300 0 0
								11000 4510 3000 0 0
								11000 4560 2700 0 0
								11000 4560 2500 0 0
								11000 4560 2000 0 0
								11000 4560 1500 0 0
								11000 4560 1000 0 0
								11000 4570 900 1 0>;
				strategy_temp_normal_low =	<11000 4110 9100 0 0
								11000 4110 9000 0 0
								11000 4110 8500 0 0
								11000 4220 8000 0 0
								11000 4220 7500 0 0
								11000 4220 7000 0 0
								11000 4370 6800 0 0
								11000 4370 6500 0 0
								11000 4370 6000 0 0
								11000 4370 5500 0 0
								11000 4470 5300 0 0
								11000 4470 5000 0 0
								11000 4470 4500 0 0
								11000 4470 4000 0 0
								11000 4520 3900 0 0
								11000 4520 3500 0 0
								11000 4560 3100 0 0
								11000 4560 3000 0 0
								11000 4560 2500 0 0
								11000 4560 2000 0 0
								11000 4560 1500 0 0
								11000 4570 1400 1 0>;
				strategy_temp_normal_high =	<11000 4110 9100 0 0
								11000 4110 9000 0 0
								11000 4110 8500 0 0
								11000 4220 8000 0 0
								11000 4220 7500 0 0
								11000 4220 7000 0 0
								11000 4370 6800 0 0
								11000 4370 6500 0 0
								11000 4370 6000 0 0
								11000 4370 5500 0 0
								11000 4470 5300 0 0
								11000 4470 5000 0 0
								11000 4470 4500 0 0
								11000 4470 4000 0 0
								11000 4520 3900 0 0
								11000 4520 3500 0 0
								11000 4560 3100 0 0
								11000 4560 3000 0 0
								11000 4560 2500 0 0
								11000 4570 2300 1 0>;
				strategy_temp_warm =		<11000 4120 1500 0 0
								11000 4120 1000 0 0
								11000 4130 500 1 0>;
			};
			strategy_soc_range_mid {
				strategy_temp_little_cold =	<11000 4150 1000 0 0
								11000 4570 500 1 0>;
				strategy_temp_cool =		<11000 4150 2000 0 0
								11000 4150 1500 0 0
								11000 4510 1300 0 0
								11000 4510 1000 0 0
								11000 4560 700 0 0
								11000 4570 600 1 0>;
				strategy_temp_little_cool =	<11000 4150 2700 0 0
								11000 4150 2500 0 0
								11000 4330 2100 0 0
								11000 4330 2000 0 0
								11000 4330 1500 0 0
								11000 4560 1300 0 0
								11000 4560 1000 0 0
								11000 4570 700 1 0>;
				strategy_temp_little_cool_high = <11000 4280 4000 0 0
								11000 4280 3500 0 0
								11000 4510 3300 0 0
								11000 4510 3000 0 0
								11000 4560 2700 0 0
								11000 4560 2500 0 0
								11000 4560 2000 0 0
								11000 4560 1500 0 0
								11000 4560 1000 0 0
								11000 4570 900 1 0>;
				strategy_temp_normal_low =	<11000 4470 4500 0 0
								11000 4470 4000 0 0
								11000 4520 3900 0 0
								11000 4520 3500 0 0
								11000 4560 3100 0 0
								11000 4560 3000 0 0
								11000 4560 2500 0 0
								11000 4560 2000 0 0
								11000 4560 1500 0 0
								11000 4570 1400 1 0>;
				strategy_temp_normal_high =	<11000 4470 5000 0 0
								11000 4470 4500 0 0
								11000 4470 4000 0 0
								11000 4520 3900 0 0
								11000 4520 3500 0 0
								11000 4560 3100 0 0
								11000 4560 3000 0 0
								11000 4560 2500 0 0
								11000 4570 2300 1 0>;
				strategy_temp_warm =		<11000 4130 1000 1 0>;
			};
			strategy_soc_range_mid_high {
				strategy_temp_little_cold =	<11000 4150 1000 0 0
								11000 4570 500 1 0>;
				strategy_temp_cool =		<11000 4150 2000 0 0
								11000 4150 1500 0 0
								11000 4510 1300 0 0
								11000 4510 1000 0 0
								11000 4560 700 0 0
								11000 4570 600 1 0>;
				strategy_temp_little_cool =	<11000 4150 2700 0 0
								11000 4150 2500 0 0
								11000 4330 2100 0 0
								11000 4330 2000 0 0
								11000 4330 1500 0 0
								11000 4560 1300 0 0
								11000 4560 1000 0 0
								11000 4570 700 1 0>;
				strategy_temp_little_cool_high = <11000 4510 3000 0 0
								11000 4560 2700 0 0
								11000 4560 2500 0 0
								11000 4560 2000 0 0
								11000 4560 1500 0 0
								11000 4560 1000 0 0
								11000 4570 900 1 0>;
				strategy_temp_normal_low =	<11000 4520 3500 0 0
								11000 4560 3100 0 0
								11000 4560 3000 0 0
								11000 4560 2500 0 0
								11000 4560 2000 0 0
								11000 4560 1500 0 0
								11000 4570 1400 1 0>;
				strategy_temp_normal_high =	<11000 4520 3500 0 0
								11000 4560 3100 0 0
								11000 4560 3000 0 0
								11000 4560 2500 0 0
								11000 4570 2300 1 0>;
				strategy_temp_warm =		<11000 4130 1000 1 0>;
			};
			strategy_soc_range_high {
				strategy_temp_little_cold =	<11000 4150 1000 0 0
								11000 4570 500 1 0>;
				strategy_temp_cool =		<11000 4150 1500 0 0
								11000 4510 1300 0 0
								11000 4510 1000 0 0
								11000 4560 700 0 0
								11000 4570 600 1 0>;
				strategy_temp_little_cool =	<11000 4330 1500 0 0
								11000 4560 1300 0 0
								11000 4560 1000 0 0
								11000 4570 700 1 0>;
				strategy_temp_little_cool_high = <11000 4560 1500 0 0
								11000 4560 1000 0 0
								11000 4570 900 1 0>;
				strategy_temp_normal_low =	<11000 4560 2000 0 0
								11000 4560 1500 0 0
								11000 4570 1400 1 0>;
				strategy_temp_normal_high =	<11000 4570 2300 1 0>;
				strategy_temp_warm =		<11000 4130 1000 1 0>;
			};
		};

		oplus,impedance_node {
			ufcs_input_impedance: ufcs_input_impedance {
				node_name = "ufcs_mos";
				default_impedance_mohm = <0>;
				default_curr_ma = <9100>;
				current_drop_table = <
					125 10000
					130 8000
					190 5000
					250 4000
					340 3000
					380 2000
					480 0
				>;
			};
		};
	};
};

&soc {
	oplus_ufcs_impedance_check: oplus,ufcs_impedance_check {
		compatible = "oplus,impedance_check";

		oplus,impedance_unit {
			oplus_ufcs_impedance_unit: oplus,ufcs_impedance_unit {
				uint_name = "ufcs";
				default_curr_ma = <9100>;
				impedance_node = <&ufcs_input_impedance>;
			};
		};
	};
};
&soc {
	oplus_chg_plc: oplus,plc_charge {
		compatible = "oplus,plc_charge";
		oplus,plc_soc = <90>;
		oplus,plc_strategy-data = <&buck_simple_strategy>;
		oplus,plc_strategy-names = "default";

		oplus_ufcs_step_strategy: oplus_ufcs_step_strategy {
			oplus,strategy_type = <PLC_STRATEGY_STEP>;
		};

		cp_2t1_simple_strategy: cp_2t1_simple_strategy {
			oplus,strategy_type = <PLC_STRATEGY_SIMPLE>;
			oplus,strategy_data {
				strategy_curr_ma = <1000 1500>;
			};
		};

		cp_1t1_simple_strategy: cp_1t1_simple_strategy {
			oplus,strategy_type = <PLC_STRATEGY_SIMPLE>;
			oplus,strategy_data {
				strategy_curr_ma = <2000 3000>;
			};
		};

		buck_simple_strategy: buck_simple_strategy {
			oplus,strategy_type = <PLC_STRATEGY_SIMPLE>;
		};
	};
};

//#endif OPLUS_FEATURE_CHG_BASIC /*for ufcs config*/

#include "oplus-chg-24811-pps.dtsi"

//#endif OPLUS_FEATURE_CHG_BASIC

